VERSION ""

NS_ :

BS_:

BU_: ACM

VAL_TABLE_ Rolling_Counter_0x85 15 "Invalid";
VAL_TABLE_ ACM_Crash_Sts 3 "Invalid Value" 2 "Invalid Value" 1 "Crash_Detected" 0 "No_Event";
VAL_TABLE_ ACM_Airbag_Deployment_Status 3 "Invalid Value" 2 "Invalid Value" 1 "Airbag_Deployment" 0 "No_Airbag_Deployment";
VAL_TABLE_ ACM_Crash_Intensity 7 "Invalid_Value" 6 "Invalid_Value" 5 "Invalid_Value" 4 "Invalid_Value" 3 "Crash_Intensity_3" 2 "Crash_Intensity_2" 1 "Crash_Intensity_1" 0 "No_Crash";
VAL_TABLE_ ACM_Front_Crash 3 "Invalid Value" 2 "Invalid Value" 1 "Front_Crash_Detected" 0 "No_Event";
VAL_TABLE_ ACM_DriverSide_Crash 3 "Invalid Value" 2 "Invalid Value" 1 "Driverside_Crash_Detected" 0 "No_Event";
VAL_TABLE_ ACM_PassSide_Crash 3 "Invalid Value" 2 "Invalid Value" 1 "PassSide_Crash_Detected" 0 "No_Event";
VAL_TABLE_ ACM_Rear_Crash 3 "Invalid Value" 2 "Invalid Value" 1 "Rear_Crash_Detected" 0 "No_Event";
VAL_TABLE_ ACM_Rollover_Crash 3 "Invalid Value" 2 "Invalid Value" 1 "Rollover_Crash_Detected" 0 "No_Event";
VAL_TABLE_ Rolling_Counter_0x381 15 "Invalid";
VAL_TABLE_ ACM_Seat_Occupancy_Passenger 3 "Failure" 2 "Not_Available" 1 "Seat Occupied" 0 "Seat_Not_Occupied";
VAL_TABLE_ ACM_Seat_Occupancy_2nd_Row_Dri_reserved 3 "Failure" 2 "Not_Available" 1 "Seat Occupied" 0 "Seat_Not_Occupied";
VAL_TABLE_ ACM_Seat_Occupancy_2nd_Row_Pas_reserved 3 "Failure" 2 "Not_Available" 1 "Seat Occupied" 0 "Seat_Not_Occupied";
VAL_TABLE_ ACM_Seat_Occupancy_2nd_Row_Mid_reserved 3 "Failure" 2 "Not_Available" 1 "Seat Occupied" 0 "Seat_Not_Occupied";
VAL_TABLE_ ACM_Seat_Belt_Status_Passenger 3 "Failure" 2 "Not_Available" 1 "Buckled" 0 "Not_buckled";
VAL_TABLE_ ACM_Seat_Belt_Status_Driver 3 "Failure" 2 "Not_Available" 1 "Buckled" 0 "Not_buckled";
VAL_TABLE_ ACM_Seat_Belt_Status_2nd_Row_Dri_reserved 3 "Failure" 2 "Not_Available" 1 "Buckled" 0 "Not_buckled";
VAL_TABLE_ ACM_Seat_Belt_Status_2nd_Row_Mid_reserved 3 "Failure" 2 "Not_Available" 1 "Buckled" 0 "Not_buckled";
VAL_TABLE_ ACM_Seat_Belt_Status_2nd_Row_Pas_reserved 3 "Failure" 2 "Not_Available" 1 "Buckled" 0 "Not_buckled";
VAL_TABLE_ ACM_Seat_Belt_Status_3rd_Row_Dri_reserved 3 "Failure" 2 "Not_Available" 1 "Buckled" 0 "Not_buckled";
VAL_TABLE_ ACM_Seat_Belt_Status_3rd_Row_Pas_reserved 3 "Failure" 2 "Not_Available" 1 "Buckled" 0 "Not_buckled";
VAL_TABLE_ Rolling_Counter_0x488 15 "Invalid";
VAL_TABLE_ ACM_Malfunction 0 "ACM_Failure" 1 "ACM_Normal_Operation";
VAL_TABLE_ ACM_Pre_Drive_Check 0 "ACM_Pre_Drive_Check" 1 "ACM_Normal_Operation";
VAL_TABLE_ ACM_in_Plant_Mode 0 "ACM_in_Plant_Mode" 1 "ACM_in_Normal_Mode";
VAL_TABLE_ ACM_PAB_Suppression 0 "Not_Suppressed" 1 "Suppressed" 2 "Function Failure" 3 "Invalid_Value";
VAL_TABLE_ ACM_Airbag_Disabled 0 "ACM_AirBag_Disabled" 1 "ACM_Normal_Operation";
VAL_TABLE_ ACM_Development_Calibration 0 "ACM_Dev_Calibrated" 1 "ACM_Normal_Operation";
VAL_TABLE_ ACM_In_Disposal_Mode 0 "ACM_In_Disposal_Mode" 1 "ACM_Normal_Operation";
VAL_TABLE_ ACM_Seatbelt_Reminder_Request 0 "Seatbelt reminder NOT activated" 1 "Seatbelt reminder activated";
VAL_TABLE_ ACM_SBR_Chime_Req 0 "No Active Chime" 1 "Active Chime";
VAL_TABLE_ ACM_SBR_Blinking_Req 0 "No Blinking" 1 "Blinking 1Hz";
VAL_TABLE_ Rolling_Counter_0x106 15 "Invalid";
VAL_TABLE_ BCM_HighBeamSts 0 "OFF" 1 "ON" 2 "Fault (Reserved)" 3 "Signal Invalid";
VAL_TABLE_ BCM_LowBeamSts 0 "OFF" 1 "ON" 2 "Fault (Reserved)" 3 "Signal Invalid";
VAL_TABLE_ BCM_PosLmpSts 0 "OFF" 1 "ON" 2 "Fault (Reserved)" 3 "Signal Invalid";
VAL_TABLE_ BCM_TurnIndicatorSts 0 "OFF" 1 "Left On" 2 "Right On" 3 "Left and Right On";
VAL_TABLE_ BCM_DayRunningLampSts_reserved 0 "OFF" 1 "ON" 2 "Fault (Reserved)" 3 "Signal Invalid";
VAL_TABLE_ BCM_ReverseLightSts 0 "OFF" 1 "ON" 2 "Fault (Reserved)" 3 "Signal Invalid";
VAL_TABLE_ BCM_StopLightSts 0 "OFF" 1 "ON" 2 "Fault (Reserved)" 3 "Signal Invalid";
VAL_TABLE_ BCM_Fr_Dimming_dome_lampSts 0 "OFF" 1 "ON" 2 "Fault (Reserved)" 3 "Signal Invalid";
VAL_TABLE_ BCM_Heated_rearglass 0 "OFF" 1 "ON" 2 "Fault (Reserved)" 3 "Signal Invalid";
VAL_TABLE_ BCM_BsdLightSts 0 "OFF" 1 "Left On" 2 "Right On" 3 "Left and Right On";
VAL_TABLE_ BCM_STAT_LightActivation 7 "Signal invalid" 6 "Reserved" 5 "Reserved" 4 "Reserved" 3 "AutoLight" 2 "LowBeam" 1 "PositionLight" 0 "OFF";
VAL_TABLE_ BCM_STAT_InteriorLight 3 "Signal invalid" 2 "Reserved" 1 "ON" 0 "OFF";
VAL_TABLE_ Rolling_Counter_0x109 15 "Invalid";
VAL_TABLE_ BCM_STAT_HazardWarn 3 "Signal invalid" 2 "Reserved" 1 "Active" 0 "Not active";
VAL_TABLE_ BCM_STAT_Horn_Reserved 3 "Signal invalid" 2 "Reserved" 1 "ON" 0 "OFF";
VAL_TABLE_ BCM_STAT_WiperStalkSW 7 "Invalid" 6 "Reserved" 5 "Reserved" 4 "High" 3 "Low/Mist" 2 "Auto" 1 "OFF" 0 "Mist (reserved)";
VAL_TABLE_ BCM_STAT_WiperStalkSW2 7 "Invalid" 6 "Reserved" 5 "Reserved" 4 "wash(Front wash)" 3 "wiper&wash" 2 "wiper (rear wiper)" 1 "OFF(rear wiper)" 0 "wiper&wash(rear wiper and rear wash)";
VAL_TABLE_ BCM_LigntSensor 1 "invalid" 0 "valid";
VAL_TABLE_ BCM_STAT_lampStalkSW1 7 "Invalid" 6 "Reserved" 5 "Reserved" 4 "Reserved" 3 "OFF" 2 "positionlight" 1 "Lowbeam" 0 "Auto";
VAL_TABLE_ BCM_STAT_lampStalkSW2 3 "Invalid" 2 "neutral status" 1 "HighBeam" 0 "FlashHighBeam";
VAL_TABLE_ Rolling_Counter_0x10a 15 "Invalid";
VAL_TABLE_ BCM_LVTop_up 1 "start Top up" 0 "stop Top up";
VAL_TABLE_ Rolling_Counter_0x112 15 "Invalid";
VAL_TABLE_ STAT_Terminal 7 "Signal invalid" 6 "Reserved" 5 "Reserved" 4 "SW update OTA (Not used in VFe34)" 3 "Engine start (eMotor running)" 2 "ON (Driver Present)" 1 "ACC (Park)" 0 "OFF(Comfort Enable)";
VAL_TABLE_ STAT_CL30s_L_Reserved 3 "Signal invalid" 2 "Failure" 1 "ON" 0 "OFF";
VAL_TABLE_ RollingCounter_0x342 15 "Invalid";
VAL_TABLE_ ABS_LRWhlSpdRaw 32767 "Invalid";
VAL_TABLE_ ABS_LRWhlSpdRawValid 1 "Valid" 0 "Invalid";
VAL_TABLE_ ABS_RRWhlSpdRaw 32767 "Invalid";
VAL_TABLE_ ABS_RRWhlSpdRawValid 1 "Valid" 0 "Invalid";
VAL_TABLE_ ABS_VehSpd 32767 "Invalid";
VAL_TABLE_ ABS_VehSpdValid 1 "Valid" 0 "Invalid";
VAL_TABLE_ RollingCounter_0x142 15 "Invalid";
VAL_TABLE_ AbsDiagSessionLampReq_Reserved 1 "lamp on" 0 "lamp off";
VAL_TABLE_ ABS_AbsCtrlActv 1 "active" 0 "inactive";
VAL_TABLE_ ABS_EbdFlgFlt 1 "failure" 0 "no failure";
VAL_TABLE_ ABS_AbsFlgFlt 1 "failure" 0 "no failure";
VAL_TABLE_ ABS_ESS_Active 1 "active" 0 "inactive";
VAL_TABLE_ ABS_LowBrakeFluid 1 "failure" 0 "no failure";
VAL_TABLE_ RollingCounter_0x132 15 "Invalid";
VAL_TABLE_ ESC_HSA_Control_Status 1 "active" 0 "inactive";
VAL_TABLE_ ESC_HSA_Status_Fault 1 " HSA Defective" 0 "HSA Normale";
VAL_TABLE_ ESC_TcsDisableSts 3 "signal invalid" 2 "reservred" 1 "disabled" 0 "enabled";
VAL_TABLE_ ESC_TcsCtrlActv 1 "active" 0 "inactive";
VAL_TABLE_ ESC_TcsFlgFlt 1 "failure" 0 "no failure";
VAL_TABLE_ ESC_EscDisableSts 1 "disabled" 0 "enabled";
VAL_TABLE_ ESC_EscCtrlActv 1 "active" 0 "inactive";
VAL_TABLE_ ESC_EscFlgFlt 1 "failure" 0 "no failure";
VAL_TABLE_ ESC_HBAFlgFlt 1 "failure" 0 "no failure";
VAL_TABLE_ ESC_HbaCtrlActv 1 "active" 0 "inactive";
VAL_TABLE_ ESC_SlopeGradeAngle 255 "Invalid";
VAL_TABLE_ ESC_MasterCylinderPressure 4095 "Invalid";
VAL_TABLE_ RollingCounter_0x3E2 15 "Invalid";
VAL_TABLE_ ESC_LateralACC 255 "Invalid";
VAL_TABLE_ ESC_LateralACC_Valid 1 "Valid" 0 "Invalid";
VAL_TABLE_ ESC_LongitudeACC 1023 "Invalid";
VAL_TABLE_ ESC_LongitudeACC_Valid 1 "Valid" 0 "Invalid";
VAL_TABLE_ ESC_VehDynYawRate 16383 "Invalid";
VAL_TABLE_ ESC_VehDynYawRate_Valid 1 "Valid" 0 "Invalid";
VAL_TABLE_ Rolling_counter_0x17E 15 "Invalid";
VAL_TABLE_ SAS_SteerWheelAngle 65535 "Invalid";
VAL_TABLE_ SAS_SteeringAngleValid 1 "Valid" 0 "Invalid";
VAL_TABLE_ SAS_SASStsSnsr 1 "sensor value valid" 0 "sensor value Invalid";
VAL_TABLE_ SAS_SteerWhlRotSpd 16383 "Invalid";
VAL_TABLE_ SAS_SteerWhlRotSpdStatus 1 "Valid" 0 "Invalid";
VAL_TABLE_ SAS_Calibrated 1 "Calibrated" 0 "Not Calibrated";
VAL_TABLE_ SAS_SASFailure 1 "No Failure" 0 "Failure";
VAL_TABLE_ RollingCounter_0x269 15 "Invalid";
VAL_TABLE_ VCU_VehicleHVStatus 3 "Reserved" 2 "ReadyToDrive" 1 "HV On" 0 "Not ready";
VAL_TABLE_ VCU_ActualGear 7 "Fault" 6 "Reserved" 5 "Reserved" 4 "Reserved" 3 "D" 2 "N" 1 "R" 0 "P reserved";
VAL_TABLE_ VCU_ActualGearValid 1 "nvalid" 0 "Valid";
VAL_TABLE_ VCU_AccPedalPosition 255 "Invalid";
VAL_TABLE_ VCU_AccPedalPositionValid 1 "Invalid" 0 "Valid";
VAL_TABLE_ VCU_TqReductionRqstResponse_Reserved 1 "active" 0 "inactive";
VAL_TABLE_ VCU_BrakePedalSts 3 "Invalid" 2 "Reserved" 1 "pressed" 0 "Not pressed";
VAL_TABLE_ CCU_ExternalTemperature 255 "Invaild";
VAL_TABLE_ CCU_ExternalTemperatureFailSts 1 "invalid" 0 "valid";
VAL_TABLE_ IPC_Sec 63 "Invalid";
VAL_TABLE_ IPC_Min 63 "Invalid";
VAL_TABLE_ IPC_Hour 31 "Invalid";
VAL_TABLE_ IPC_Day 31 "Invalid";
VAL_TABLE_ IPC_Month 15 "Invalid";
VAL_TABLE_ IPC_Year 255 "Invalid";
VAL_TABLE_ IPC_SelfCheckStatus 1 "self-check finish" 0 "self-checking";
VAL_TABLE_ Rolling_Counter_0x20C 15 "Invalid";
VAL_TABLE_ IPC_ODO 1048575 "Invalid";
VAL_TABLE_ VCU_RegenLevel_Feed 3 "invalid" 2 "High" 1 "Low" 0 "none";
VAL_TABLE_ VCU_RBCSts 1 "active" 0 "incative";
VAL_TABLE_ VCU_RDCSts 1 "active" 0 "incative";
VAL_TABLE_ VCU_Veh_ERR 1 "Error" 0 "Normal";
VAL_TABLE_ VCU_DrvSys_ERR 1 "Error" 0 "Normal";
VAL_TABLE_ VCU_PackSys_ERR 1 "Error" 0 "Normal";
VAL_TABLE_ VCU_TBOX_Veh_STS_Reserved 3 "Other" 2 "Off" 1 "Start" 0 "Invalid";
VAL_TABLE_ VCU_VehChg_STS 3 "Charge fault" 2 "Charging complete" 1 "Charging in progress" 0 "Charging not in progress";
VAL_TABLE_ VCU_BatterVoltage_Reserved 255 "Invalid";
VAL_TABLE_ VCU_BatteryVoltErr_Reserved 1 "warning" 0 "no warning";
VAL_TABLE_ VCU_MotorCoolingCircuitErr_Reserved 1 "Error" 0 "Normal";
VAL_TABLE_ VCU_PackCoolingCircuitErr_Reserved 1 "Error" 0 "Normal";
VAL_TABLE_ VCU_VehicleHVStatus 3 "Reserved" 2 "ReadyToDrive" 1 "HV On" 0 "Not ready";
VAL_TABLE_ VCU_InstantPowerConsump 1023 "Invalid";
VAL_TABLE_ VCU_AveragePowerConsump 1023 "Invalid";
VAL_TABLE_ VCU_BrakePedalSts 3 "Invalid" 2 "Reserved" 1 "pressed" 0 "Not pressed";
VAL_TABLE_ Rolling_Counter_0x1F8 15 "Invalid";
VAL_TABLE_ EDS_output_trq_FR 65535 "Invalid";
VAL_TABLE_ EDS_output_trqValid_FR 1 "valid" 0 "invalid";
VAL_TABLE_ EDS_Spd_FR 65535 "Invalid";
VAL_TABLE_ EDS_SpdValid_FR 1 "valid" 0 "invalid";
VAL_TABLE_ EDS_MotorDriveSts_FR 3 "Invaild" 2 "regen control" 1 "Drive control" 0 "Zero control";
VAL_TABLE_ EDS_Work_STS_FR 15 "invaild" 14 "power off" 13 "Failure" 12 "after run" 11 "shut down" 5 "HVReady" 4 "normal" 3 "precharge" 2 "standby" 1 "init" 0 "default";
VAL_TABLE_ EDS_powoff_req_FR 1 "(Request high voltage power down)" 0 "(No request)";
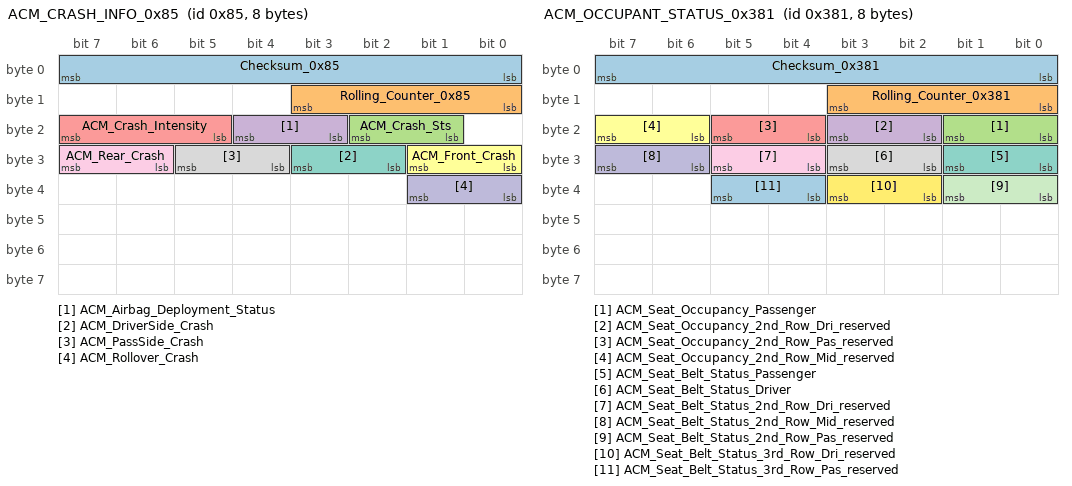
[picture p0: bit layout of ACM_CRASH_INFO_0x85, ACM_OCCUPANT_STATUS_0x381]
BO_ 133 ACM_CRASH_INFO_0x85: 8 ACM
 SG_ Checksum_0x85 : 7|8@0+ (1,0) [0|255] "" Vector__XXX
 SG_ Rolling_Counter_0x85 : 11|4@0+ (1,0) [0|15] "" Vector__XXX
 SG_ ACM_Crash_Sts : 18|2@0+ (1,0) [0|3] "" Vector__XXX
 SG_ ACM_Airbag_Deployment_Status : 20|2@0+ (1,0) [0|3] "" Vector__XXX
 SG_ ACM_Crash_Intensity : 23|3@0+ (1,0) [0|7] "" Vector__XXX
 SG_ ACM_Front_Crash : 25|2@0+ (1,0) [0|3] "" Vector__XXX
 SG_ ACM_DriverSide_Crash : 27|2@0+ (1,0) [0|3] "" Vector__XXX
 SG_ ACM_PassSide_Crash : 29|2@0+ (1,0) [0|3] "" Vector__XXX
 SG_ ACM_Rear_Crash : 31|2@0+ (1,0) [0|3] "" Vector__XXX
 SG_ ACM_Rollover_Crash : 33|2@0+ (1,0) [0|3] "" Vector__XXX
BO_ 897 ACM_OCCUPANT_STATUS_0x381: 8 ACM
 SG_ Checksum_0x381 : 7|8@0+ (1,0) [0|255] "" Vector__XXX
 SG_ Rolling_Counter_0x381 : 11|4@0+ (1,0) [0|15] "" Vector__XXX
 SG_ ACM_Seat_Occupancy_Passenger : 17|2@0+ (1,0) [0|3] "" Vector__XXX
 SG_ ACM_Seat_Occupancy_2nd_Row_Dri_reserved : 19|2@0+ (1,0) [0|3] "" Vector__XXX
 SG_ ACM_Seat_Occupancy_2nd_Row_Pas_reserved : 21|2@0+ (1,0) [0|3] "" Vector__XXX
 SG_ ACM_Seat_Occupancy_2nd_Row_Mid_reserved : 23|2@0+ (1,0) [0|3] "" Vector__XXX
 SG_ ACM_Seat_Belt_Status_Passenger : 25|2@0+ (1,0) [0|3] "" Vector__XXX
 SG_ ACM_Seat_Belt_Status_Driver : 27|2@0+ (1,0) [0|3] "" Vector__XXX
 SG_ ACM_Seat_Belt_Status_2nd_Row_Dri_reserved : 29|2@0+ (1,0) [0|3] "" Vector__XXX
 SG_ ACM_Seat_Belt_Status_2nd_Row_Mid_reserved : 31|2@0+ (1,0) [0|3] "" Vector__XXX
 SG_ ACM_Seat_Belt_Status_2nd_Row_Pas_reserved : 33|2@0+ (1,0) [0|3] "" Vector__XXX
 SG_ ACM_Seat_Belt_Status_3rd_Row_Dri_reserved : 35|2@0+ (1,0) [0|3] "" Vector__XXX
 SG_ ACM_Seat_Belt_Status_3rd_Row_Pas_reserved : 37|2@0+ (1,0) [0|3] "" Vector__XXX
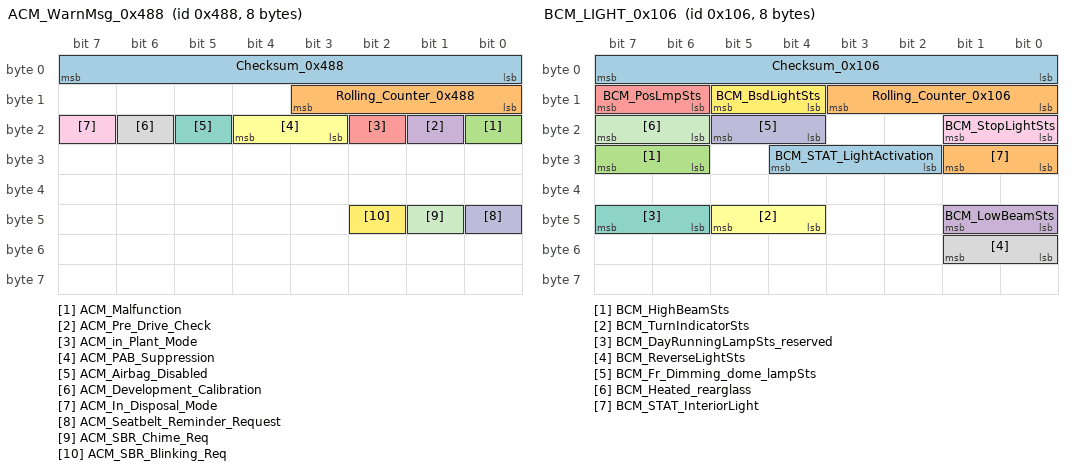
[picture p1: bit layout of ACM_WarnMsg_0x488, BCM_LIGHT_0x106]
BO_ 1160 ACM_WarnMsg_0x488: 8 ACM
 SG_ Checksum_0x488 : 7|8@0+ (1,0) [0|255] "" Vector__XXX
 SG_ Rolling_Counter_0x488 : 11|4@0+ (1,0) [0|15] "" Vector__XXX
 SG_ ACM_Malfunction : 16|1@0+ (1,0) [0|1] "" Vector__XXX
 SG_ ACM_Pre_Drive_Check : 17|1@0+ (1,0) [0|1] "Bit" Vector__XXX
 SG_ ACM_in_Plant_Mode : 18|1@0+ (1,0) [0|1] "Bit" Vector__XXX
 SG_ ACM_PAB_Suppression : 20|2@0+ (1,0) [0|3] "Bit" Vector__XXX
 SG_ ACM_Airbag_Disabled : 21|1@0+ (1,0) [0|1] "" Vector__XXX
 SG_ ACM_Development_Calibration : 22|1@0+ (1,0) [0|1] "" Vector__XXX
 SG_ ACM_In_Disposal_Mode : 23|1@0+ (1,0) [0|1] "" Vector__XXX
 SG_ ACM_Seatbelt_Reminder_Request : 40|1@0+ (1,0) [0|1] "" Vector__XXX
 SG_ ACM_SBR_Chime_Req : 41|1@0+ (1,0) [0|1] "" Vector__XXX
 SG_ ACM_SBR_Blinking_Req : 42|1@0+ (1,0) [0|1] "" Vector__XXX
BO_ 262 BCM_LIGHT_0x106: 8 Vector__XXX
 SG_ Checksum_0x106 : 7|8@0+ (1,0) [0|255] "" ACM
 SG_ Rolling_Counter_0x106 : 11|4@0+ (1,0) [0|15] "" ACM
 SG_ BCM_HighBeamSts : 31|2@0+ (1,0) [0|3] "" Vector__XXX
 SG_ BCM_LowBeamSts : 41|2@0+ (1,0) [0|3] "" Vector__XXX
 SG_ BCM_PosLmpSts : 15|2@0+ (1,0) [0|3] "" Vector__XXX
 SG_ BCM_TurnIndicatorSts : 45|2@0+ (1,0) [0|3] "" ACM
 SG_ BCM_DayRunningLampSts_reserved : 47|2@0+ (1,0) [0|3] "" Vector__XXX
 SG_ BCM_ReverseLightSts : 49|2@0+ (1,0) [0|3] "" Vector__XXX
 SG_ BCM_StopLightSts : 17|2@0+ (1,0) [0|3] "" Vector__XXX
 SG_ BCM_Fr_Dimming_dome_lampSts : 21|2@0+ (1,0) [0|3] "" Vector__XXX
 SG_ BCM_Heated_rearglass : 23|2@0+ (1,0) [0|3] "" Vector__XXX
 SG_ BCM_BsdLightSts : 13|2@0+ (1,0) [0|3] "" Vector__XXX
 SG_ BCM_STAT_LightActivation : 28|3@0+ (1,0) [0|7] "" Vector__XXX
 SG_ BCM_STAT_InteriorLight : 25|2@0+ (1,0) [0|3] "Bit" Vector__XXX
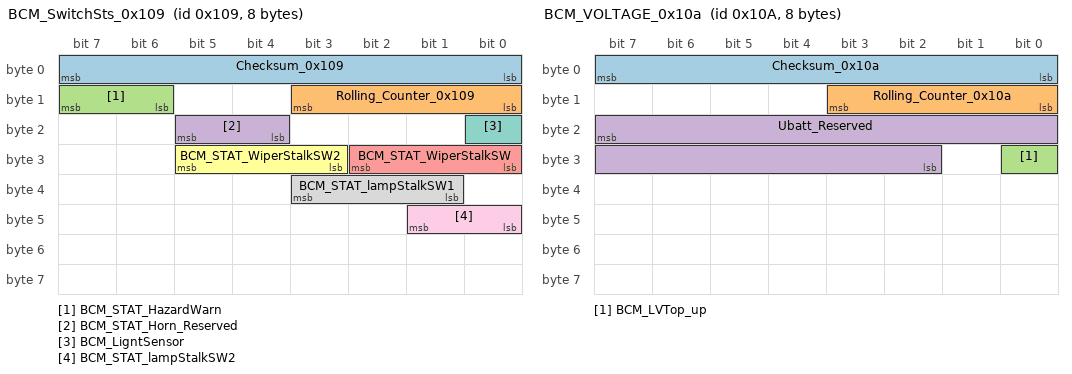
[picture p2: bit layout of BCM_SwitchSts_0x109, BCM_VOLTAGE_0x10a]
BO_ 265 BCM_SwitchSts_0x109: 8 Vector__XXX
 SG_ Checksum_0x109 : 7|8@0+ (1,0) [0|255] "" ACM
 SG_ Rolling_Counter_0x109 : 11|4@0+ (1,0) [0|15] "" ACM
 SG_ BCM_STAT_HazardWarn : 15|2@0+ (1,0) [0|3] "" ACM
 SG_ BCM_STAT_Horn_Reserved : 21|2@0+ (1,0) [0|3] "" Vector__XXX
 SG_ BCM_STAT_WiperStalkSW : 26|3@0+ (1,0) [0|7] "" Vector__XXX
 SG_ BCM_STAT_WiperStalkSW2 : 29|3@0+ (1,0) [0|7] "" Vector__XXX
 SG_ BCM_LigntSensor : 16|1@0+ (1,0) [0|1] "" Vector__XXX
 SG_ BCM_STAT_lampStalkSW1 : 35|3@0+ (1,0) [0|7] "" Vector__XXX
 SG_ BCM_STAT_lampStalkSW2 : 41|2@0+ (1,0) [0|3] "" Vector__XXX
BO_ 266 BCM_VOLTAGE_0x10a: 8 Vector__XXX
 SG_ Checksum_0x10a : 7|8@0+ (1,0) [0|255] "" ACM
 SG_ Rolling_Counter_0x10a : 11|4@0+ (1,0) [0|15] "" ACM
 SG_ BCM_LVTop_up : 24|1@0+ (1,0) [0|1] "" Vector__XXX
 SG_ Ubatt_Reserved : 23|14@0+ (0.001,3) [3|18] "V" ACM
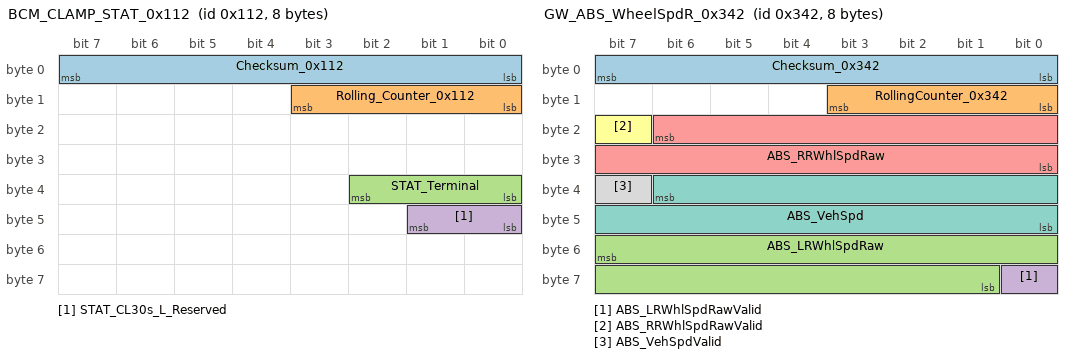
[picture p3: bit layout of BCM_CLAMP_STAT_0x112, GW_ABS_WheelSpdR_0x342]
BO_ 274 BCM_CLAMP_STAT_0x112: 8 Vector__XXX
 SG_ Checksum_0x112 : 7|8@0+ (1,0) [0|255] "" ACM
 SG_ Rolling_Counter_0x112 : 11|4@0+ (1,0) [0|15] "" ACM
 SG_ STAT_Terminal : 34|3@0+ (1,0) [0|7] "Bit" ACM
 SG_ STAT_CL30s_L_Reserved : 41|2@0+ (1,0) [0|3] "Bit" Vector__XXX
BO_ 834 GW_ABS_WheelSpdR_0x342: 8 Vector__XXX
 SG_ Checksum_0x342 : 7|8@0+ (1,0) [0|255] "" ACM
 SG_ RollingCounter_0x342 : 11|4@0+ (1,0) [0|15] "" ACM
 SG_ ABS_LRWhlSpdRaw : 55|15@0+ (0.01,0) [0|327.66] "kph" Vector__XXX
 SG_ ABS_LRWhlSpdRawValid : 56|1@0+ (1,0) [0|1] "" Vector__XXX
 SG_ ABS_RRWhlSpdRaw : 22|15@0+ (0.01,0) [0|327.66] "kph" Vector__XXX
 SG_ ABS_RRWhlSpdRawValid : 23|1@0+ (1,0) [0|1] "" Vector__XXX
 SG_ ABS_VehSpd : 38|15@0+ (0.01,0) [0|327.66] "kph" ACM
 SG_ ABS_VehSpdValid : 39|1@0+ (1,0) [0|1] "" ACM
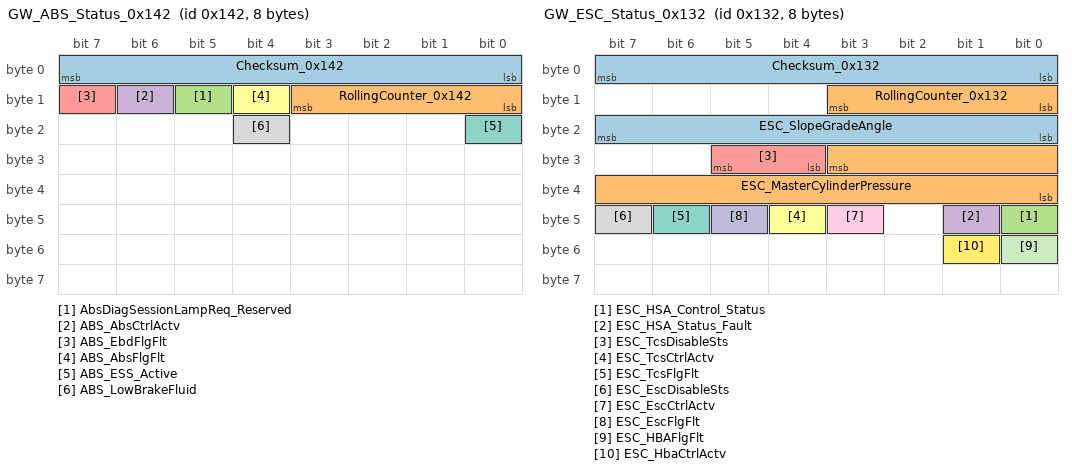
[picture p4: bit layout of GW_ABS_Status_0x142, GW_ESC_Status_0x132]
BO_ 322 GW_ABS_Status_0x142: 8 Vector__XXX
 SG_ Checksum_0x142 : 7|8@0+ (1,0) [0|255] "" ACM
 SG_ RollingCounter_0x142 : 11|4@0+ (1,0) [0|15] "" ACM
 SG_ AbsDiagSessionLampReq_Reserved : 13|1@0+ (1,0) [0|1] "" Vector__XXX
 SG_ ABS_AbsCtrlActv : 14|1@0+ (1,0) [0|1] "" ACM
 SG_ ABS_EbdFlgFlt : 15|1@0+ (1,0) [0|1] "" Vector__XXX
 SG_ ABS_AbsFlgFlt : 12|1@0+ (1,0) [0|1] "" ACM
 SG_ ABS_ESS_Active : 16|1@0+ (1,0) [0|1] "" Vector__XXX
 SG_ ABS_LowBrakeFluid : 20|1@0+ (1,0) [0|1] "" Vector__XXX
BO_ 306 GW_ESC_Status_0x132: 8 Vector__XXX
 SG_ Checksum_0x132 : 7|8@0+ (1,0) [0|255] "" ACM
 SG_ RollingCounter_0x132 : 11|4@0+ (1,0) [0|15] "" ACM
 SG_ ESC_HSA_Control_Status : 40|1@0+ (1,0) [0|1] "" Vector__XXX
 SG_ ESC_HSA_Status_Fault : 41|1@0+ (1,0) [0|1] "" Vector__XXX
 SG_ ESC_TcsDisableSts : 29|2@0+ (1,0) [0|3] "" Vector__XXX
 SG_ ESC_TcsCtrlActv : 44|1@0+ (1,0) [0|1] "" Vector__XXX
 SG_ ESC_TcsFlgFlt : 46|1@0+ (1,0) [0|1] "" Vector__XXX
 SG_ ESC_EscDisableSts : 47|1@0+ (1,0) [0|1] "" Vector__XXX
 SG_ ESC_EscCtrlActv : 43|1@0+ (1,0) [0|1] "" ACM
 SG_ ESC_EscFlgFlt : 45|1@0+ (1,0) [0|1] "" ACM
 SG_ ESC_HBAFlgFlt : 48|1@0+ (1,0) [0|1] "" Vector__XXX
 SG_ ESC_HbaCtrlActv : 49|1@0+ (1,0) [0|1] "" Vector__XXX
 SG_ ESC_SlopeGradeAngle : 23|8@0+ (0.35433,-45) [-45|45] "deg" Vector__XXX
 SG_ ESC_MasterCylinderPressure : 27|12@0+ (0.1,-100) [-100|309.4] "bar" Vector__XXX
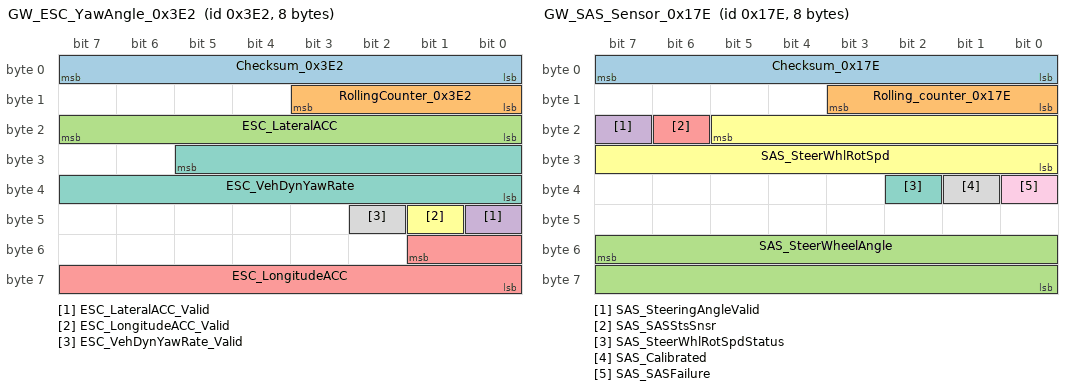
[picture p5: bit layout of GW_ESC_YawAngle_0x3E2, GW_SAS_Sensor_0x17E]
BO_ 994 GW_ESC_YawAngle_0x3E2: 8 Vector__XXX
 SG_ Checksum_0x3E2 : 7|8@0+ (1,0) [0|255] "" ACM
 SG_ RollingCounter_0x3E2 : 11|4@0+ (1,0) [0|15] "" ACM
 SG_ ESC_LateralACC : 23|8@0+ (0.01587,-2.0193) [-2.0193|2.0193] "g" Vector__XXX
 SG_ ESC_LateralACC_Valid : 40|1@0+ (1,0) [0|1] "" Vector__XXX
 SG_ ESC_LongitudeACC : 49|10@0+ (0.00392,-1.9929) [-1.9929|1.9929] "g" Vector__XXX
 SG_ ESC_LongitudeACC_Valid : 41|1@0+ (1,0) [0|1] "" Vector__XXX
 SG_ ESC_VehDynYawRate : 29|14@0+ (0.03125,-256) [-256|255.96875] "deg/s" ACM
 SG_ ESC_VehDynYawRate_Valid : 42|1@0+ (1,0) [0|1] "" ACM
BO_ 382 GW_SAS_Sensor_0x17E: 8 Vector__XXX
 SG_ Checksum_0x17E : 7|8@0+ (1,0) [0|255] "" ACM
 SG_ Rolling_counter_0x17E : 11|4@0+ (1,0) [0|15] "" ACM
 SG_ SAS_SteerWheelAngle : 55|16@0+ (0.0238,-780) [-780|779.7] "deg" ACM
 SG_ SAS_SteeringAngleValid : 23|1@0+ (1,0) [0|1] "" ACM
 SG_ SAS_SASStsSnsr : 22|1@0+ (1,0) [0|1] "" Vector__XXX
 SG_ SAS_SteerWhlRotSpd : 21|14@0+ (0.125,-1024) [-1024|1023.75] "degs" Vector__XXX
 SG_ SAS_SteerWhlRotSpdStatus : 34|1@0+ (1,0) [0|1] "" Vector__XXX
 SG_ SAS_Calibrated : 33|1@0+ (1,0) [0|1] "" Vector__XXX
 SG_ SAS_SASFailure : 32|1@0+ (1,0) [0|1] "" Vector__XXX
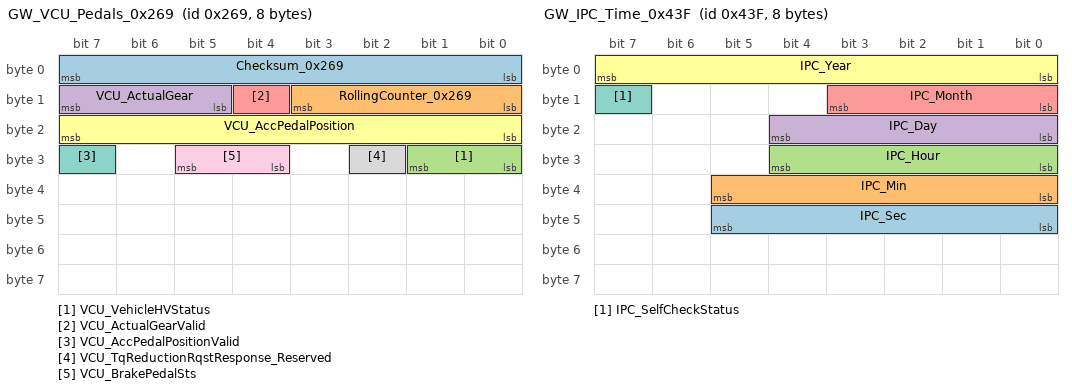
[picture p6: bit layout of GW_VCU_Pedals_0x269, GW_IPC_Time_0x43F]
BO_ 617 GW_VCU_Pedals_0x269: 8 Vector__XXX
 SG_ Checksum_0x269 : 7|8@0+ (1,0) [0|255] "" ACM
 SG_ RollingCounter_0x269 : 11|4@0+ (1,0) [0|15] "" ACM
 SG_ VCU_VehicleHVStatus : 25|2@0+ (1,0) [0|3] "" ACM
 SG_ VCU_ActualGear : 15|3@0+ (1,0) [0|7] "" Vector__XXX
 SG_ VCU_ActualGearValid : 12|1@0+ (1,0) [0|1] "" Vector__XXX
 SG_ VCU_AccPedalPosition : 23|8@0+ (0.4,0) [0|100] "%" ACM
 SG_ VCU_AccPedalPositionValid : 31|1@0+ (1,0) [0|1] "" ACM
 SG_ VCU_TqReductionRqstResponse_Reserved : 26|1@0+ (1,0) [0|1] "" Vector__XXX
 SG_ VCU_BrakePedalSts : 29|2@0+ (1,0) [0|3] "" ACM
BO_ 814 GW_CCU_Info_0x32E: 8 Vector__XXX
 SG_ CCU_ExternalTemperature : 7|8@0+ (0.5,-40) [-40|87] "°C" ACM
 SG_ CCU_ExternalTemperatureFailSts : 8|1@0+ (1,0) [0|1] "" ACM
BO_ 1087 GW_IPC_Time_0x43F: 8 Vector__XXX
 SG_ IPC_Sec : 45|6@0+ (1,0) [0|59] "second" ACM
 SG_ IPC_Min : 37|6@0+ (1,0) [0|59] "min" ACM
 SG_ IPC_Hour : 28|5@0+ (1,0) [0|23] "hour" ACM
 SG_ IPC_Day : 20|5@0+ (1,0) [1|31] "" ACM
 SG_ IPC_Month : 11|4@0+ (1,0) [1|12] "" ACM
 SG_ IPC_Year : 7|8@0+ (1,2000) [2000|2255] "" ACM
 SG_ IPC_SelfCheckStatus : 15|1@0+ (1,0) [0|1] "" ACM
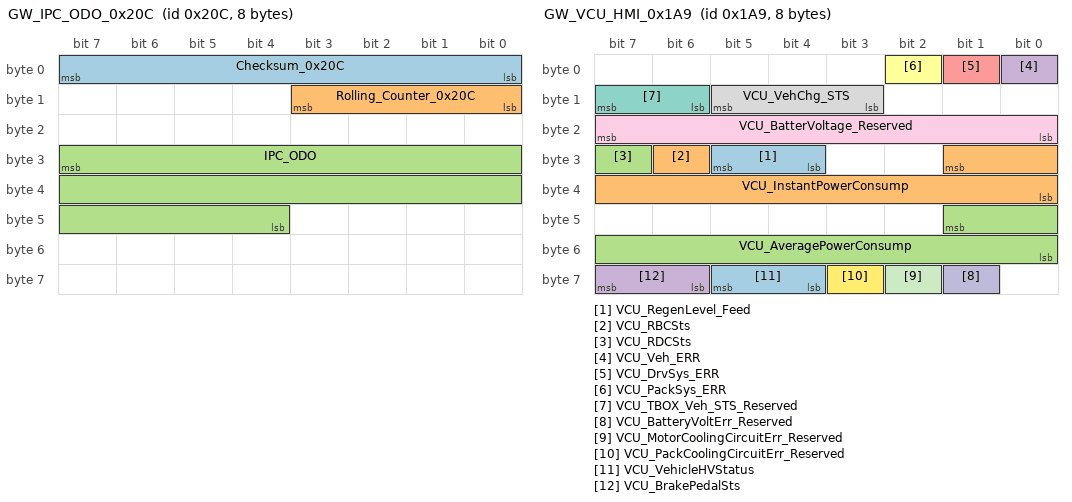
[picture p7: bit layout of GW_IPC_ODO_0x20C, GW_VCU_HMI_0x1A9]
BO_ 524 GW_IPC_ODO_0x20C: 8 Vector__XXX
 SG_ Checksum_0x20C : 7|8@0+ (1,0) [0|255] "" ACM
 SG_ Rolling_Counter_0x20C : 11|4@0+ (1,0) [0|15] "" ACM
 SG_ IPC_ODO : 31|20@0+ (1,0) [0|999999] "km" ACM
BO_ 425 GW_VCU_HMI_0x1A9: 8 Vector__XXX
 SG_ VCU_RegenLevel_Feed : 29|2@0+ (1,0) [0|3] "" Vector__XXX
 SG_ VCU_RBCSts : 30|1@0+ (1,0) [0|1] "" Vector__XXX
 SG_ VCU_RDCSts : 31|1@0+ (1,0) [0|1] "" Vector__XXX
 SG_ VCU_Veh_ERR : 0|1@0+ (1,0) [0|1] "" Vector__XXX
 SG_ VCU_DrvSys_ERR : 1|1@0+ (1,0) [0|1] "" Vector__XXX
 SG_ VCU_PackSys_ERR : 2|1@0+ (1,0) [0|1] "" Vector__XXX
 SG_ VCU_TBOX_Veh_STS_Reserved : 15|2@0+ (1,0) [0|3] "" Vector__XXX
 SG_ VCU_VehChg_STS : 13|3@0+ (1,0) [0|7] "" Vector__XXX
 SG_ VCU_BatterVoltage_Reserved : 23|8@0+ (0.07,0) [0|17.85] "V" ACM
 SG_ VCU_BatteryVoltErr_Reserved : 57|1@0+ (1,0) [0|1] "" Vector__XXX
 SG_ VCU_MotorCoolingCircuitErr_Reserved : 58|1@0+ (1,0) [0|1] "" Vector__XXX
 SG_ VCU_PackCoolingCircuitErr_Reserved : 59|1@0+ (1,0) [0|1] "" Vector__XXX
 SG_ VCU_VehicleHVStatus : 61|2@0+ (1,0) [0|3] "" Vector__XXX
 SG_ VCU_InstantPowerConsump : 25|10@0+ (0.1,0) [0|100] "kwh/100km" Vector__XXX
 SG_ VCU_AveragePowerConsump : 41|10@0+ (0.1,0) [0|100] "kwh/100km" Vector__XXX
 SG_ VCU_BrakePedalSts : 63|2@0+ (1,0) [0|3] "" Vector__XXX
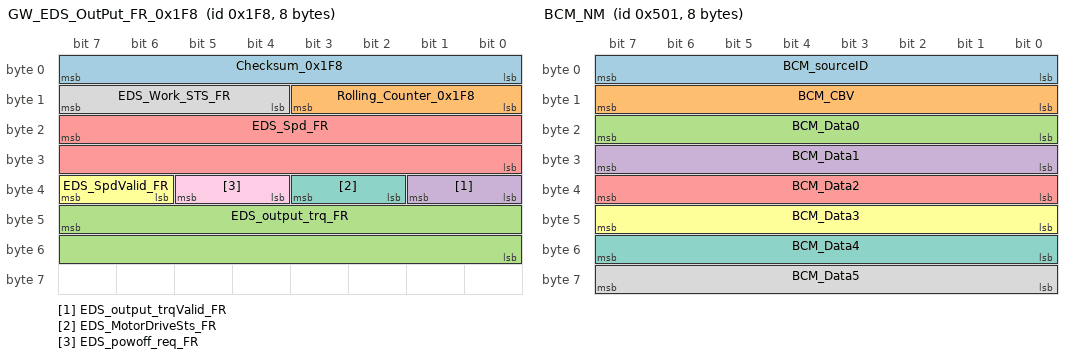
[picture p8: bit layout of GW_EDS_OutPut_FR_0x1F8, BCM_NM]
BO_ 504 GW_EDS_OutPut_FR_0x1F8: 8 Vector__XXX
 SG_ Checksum_0x1F8 : 7|8@0+ (1,0) [0|255] "" ACM
 SG_ Rolling_Counter_0x1F8 : 11|4@0+ (1,0) [0|15] "" ACM
 SG_ EDS_output_trq_FR : 47|16@0+ (1,-2000) [-2000|2000] "Nm" Vector__XXX
 SG_ EDS_output_trqValid_FR : 33|2@0+ (1,0) [0|1] "" Vector__XXX
 SG_ EDS_Spd_FR : 23|16@0+ (1,-20000) [-20000|20000] "rpm" ACM
 SG_ EDS_SpdValid_FR : 39|2@0+ (1,0) [0|1] "" ACM
 SG_ EDS_MotorDriveSts_FR : 35|2@0+ (1,0) [0|3] "" Vector__XXX
 SG_ EDS_Work_STS_FR : 15|4@0+ (1,0) [0|15] "" Vector__XXX
 SG_ EDS_powoff_req_FR : 37|2@0+ (1,0) [0|1] "" Vector__XXX
BO_ 1281 BCM_NM: 8 Vector__XXX
 SG_ BCM_sourceID : 7|8@0+ (1,0) [0|255] "" ACM
 SG_ BCM_CBV : 15|8@0+ (1,0) [0|255] "" ACM
 SG_ BCM_Data0 : 23|8@0+ (1,0) [0|255] "" ACM
 SG_ BCM_Data1 : 31|8@0+ (1,0) [0|255] "" ACM
 SG_ BCM_Data2 : 39|8@0+ (1,0) [0|255] "" ACM
 SG_ BCM_Data3 : 47|8@0+ (1,0) [0|255] "" ACM
 SG_ BCM_Data4 : 55|8@0+ (1,0) [0|255] "" ACM
 SG_ BCM_Data5 : 63|8@0+ (1,0) [0|255] "" ACM
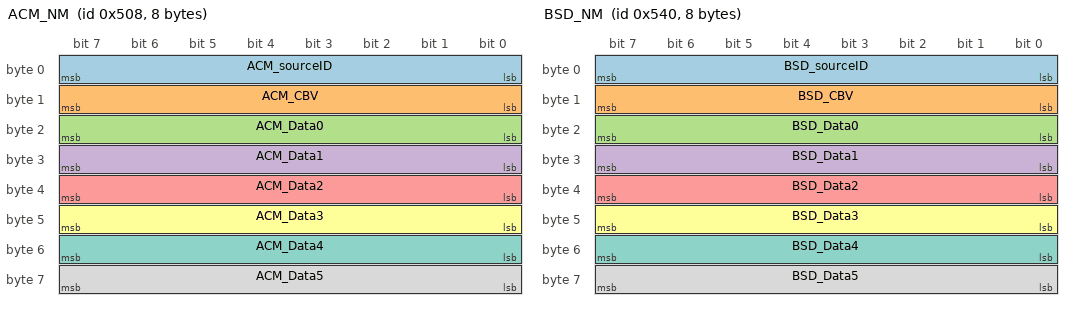
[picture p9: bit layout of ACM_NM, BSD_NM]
BO_ 1288 ACM_NM: 8 ACM
 SG_ ACM_sourceID : 7|8@0+ (1,0) [0|255] "" Vector__XXX
 SG_ ACM_CBV : 15|8@0+ (1,0) [0|255] "" Vector__XXX
 SG_ ACM_Data0 : 23|8@0+ (1,0) [0|255] "" Vector__XXX
 SG_ ACM_Data1 : 31|8@0+ (1,0) [0|255] "" Vector__XXX
 SG_ ACM_Data2 : 39|8@0+ (1,0) [0|255] "" Vector__XXX
 SG_ ACM_Data3 : 47|8@0+ (1,0) [0|255] "" Vector__XXX
 SG_ ACM_Data4 : 55|8@0+ (1,0) [0|255] "" Vector__XXX
 SG_ ACM_Data5 : 63|8@0+ (1,0) [0|255] "" Vector__XXX
BO_ 1344 BSD_NM: 8 Vector__XXX
 SG_ BSD_sourceID : 7|8@0+ (1,0) [0|255] "" ACM
 SG_ BSD_CBV : 15|8@0+ (1,0) [0|255] "" ACM
 SG_ BSD_Data0 : 23|8@0+ (1,0) [0|255] "" ACM
 SG_ BSD_Data1 : 31|8@0+ (1,0) [0|255] "" ACM
 SG_ BSD_Data2 : 39|8@0+ (1,0) [0|255] "" ACM
 SG_ BSD_Data3 : 47|8@0+ (1,0) [0|255] "" ACM
 SG_ BSD_Data4 : 55|8@0+ (1,0) [0|255] "" ACM
 SG_ BSD_Data5 : 63|8@0+ (1,0) [0|255] "" ACM
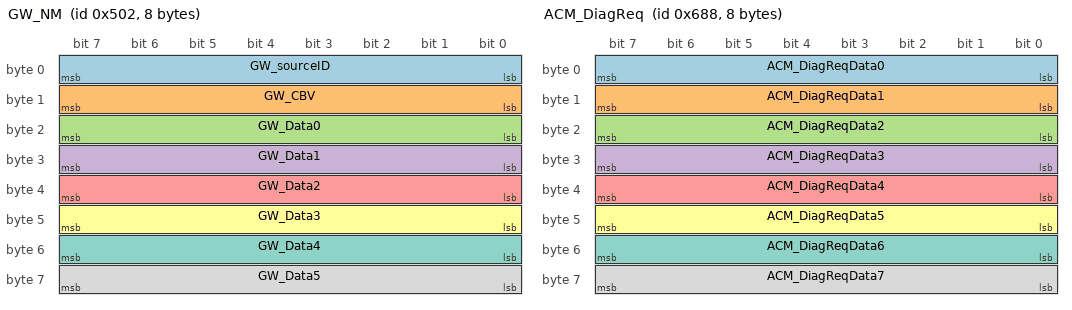
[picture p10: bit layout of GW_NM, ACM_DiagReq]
BO_ 1282 GW_NM: 8 Vector__XXX
 SG_ GW_sourceID : 7|8@0+ (1,0) [0|255] "" ACM
 SG_ GW_CBV : 15|8@0+ (1,0) [0|255] "" ACM
 SG_ GW_Data0 : 23|8@0+ (1,0) [0|255] "" ACM
 SG_ GW_Data1 : 31|8@0+ (1,0) [0|255] "" ACM
 SG_ GW_Data2 : 39|8@0+ (1,0) [0|255] "" ACM
 SG_ GW_Data3 : 47|8@0+ (1,0) [0|255] "" ACM
 SG_ GW_Data4 : 55|8@0+ (1,0) [0|255] "" ACM
 SG_ GW_Data5 : 63|8@0+ (1,0) [0|255] "" ACM
BO_ 1672 ACM_DiagReq: 8 Vector__XXX
 SG_ ACM_DiagReqData0 : 7|8@0+ (1,0) [0|255] "" ACM
 SG_ ACM_DiagReqData1 : 15|8@0+ (1,0) [0|255] "" ACM
 SG_ ACM_DiagReqData2 : 23|8@0+ (1,0) [0|255] "" ACM
 SG_ ACM_DiagReqData3 : 31|8@0+ (1,0) [0|255] "" ACM
 SG_ ACM_DiagReqData4 : 39|8@0+ (1,0) [0|255] "" ACM
 SG_ ACM_DiagReqData5 : 47|8@0+ (1,0) [0|255] "" ACM
 SG_ ACM_DiagReqData6 : 55|8@0+ (1,0) [0|255] "" ACM
 SG_ ACM_DiagReqData7 : 63|8@0+ (1,0) [0|255] "" ACM
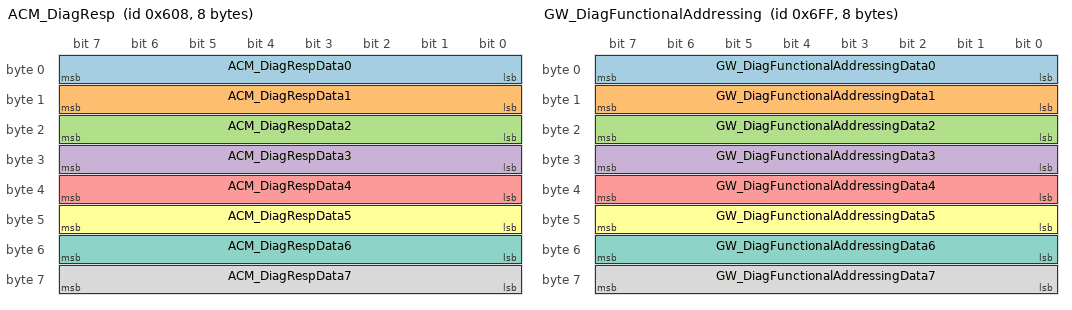
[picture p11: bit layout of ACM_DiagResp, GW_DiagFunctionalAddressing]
BO_ 1544 ACM_DiagResp: 8 ACM
 SG_ ACM_DiagRespData0 : 7|8@0+ (1,0) [0|255] "" Vector__XXX
 SG_ ACM_DiagRespData1 : 15|8@0+ (1,0) [0|255] "" Vector__XXX
 SG_ ACM_DiagRespData2 : 23|8@0+ (1,0) [0|255] "" Vector__XXX
 SG_ ACM_DiagRespData3 : 31|8@0+ (1,0) [0|255] "" Vector__XXX
 SG_ ACM_DiagRespData4 : 39|8@0+ (1,0) [0|255] "" Vector__XXX
 SG_ ACM_DiagRespData5 : 47|8@0+ (1,0) [0|255] "" Vector__XXX
 SG_ ACM_DiagRespData6 : 55|8@0+ (1,0) [0|255] "" Vector__XXX
 SG_ ACM_DiagRespData7 : 63|8@0+ (1,0) [0|255] "" Vector__XXX
BO_ 1791 GW_DiagFunctionalAddressing: 8 Vector__XXX
 SG_ GW_DiagFunctionalAddressingData0 : 7|8@0+ (1,0) [0|255] "" ACM
 SG_ GW_DiagFunctionalAddressingData1 : 15|8@0+ (1,0) [0|255] "" ACM
 SG_ GW_DiagFunctionalAddressingData2 : 23|8@0+ (1,0) [0|255] "" ACM
 SG_ GW_DiagFunctionalAddressingData3 : 31|8@0+ (1,0) [0|255] "" ACM
 SG_ GW_DiagFunctionalAddressingData4 : 39|8@0+ (1,0) [0|255] "" ACM
 SG_ GW_DiagFunctionalAddressingData5 : 47|8@0+ (1,0) [0|255] "" ACM
 SG_ GW_DiagFunctionalAddressingData6 : 55|8@0+ (1,0) [0|255] "" ACM
 SG_ GW_DiagFunctionalAddressingData7 : 63|8@0+ (1,0) [0|255] "" ACM
CM_ SG_ 133 Checksum_0x85 "Checksum";
CM_ SG_ 133 Rolling_Counter_0x85 "Rolling Counter";
CM_ SG_ 133 ACM_Crash_Sts "Crash status";
CM_ SG_ 133 ACM_Airbag_Deployment_Status "Signal to indicate if airbag/pretensioner/pyrofuse is deployed";
CM_ SG_ 133 ACM_Crash_Intensity "Indicate crash intensity level";
CM_ SG_ 133 ACM_Front_Crash "Output information for direction of crash";
CM_ SG_ 133 ACM_DriverSide_Crash "Output information for direction of crash";
CM_ SG_ 133 ACM_PassSide_Crash "Output information for direction of crash";
CM_ SG_ 133 ACM_Rear_Crash "Output information for direction of crash";
CM_ SG_ 133 ACM_Rollover_Crash "Output information for direction of crash";
CM_ SG_ 897 Checksum_0x381 "Checksum";
CM_ SG_ 897 Rolling_Counter_0x381 "Rolling Counter";
CM_ SG_ 897 ACM_Seat_Occupancy_Passenger "Signal to indicate status of occupancy";
CM_ SG_ 897 ACM_Seat_Occupancy_2nd_Row_Dri_reserved "Signal to indicate status of occupancy";
CM_ SG_ 897 ACM_Seat_Occupancy_2nd_Row_Pas_reserved "Signal to indicate status of occupancy";
CM_ SG_ 897 ACM_Seat_Occupancy_2nd_Row_Mid_reserved "Signal to indicate status of occupancy";
CM_ SG_ 897 ACM_Seat_Belt_Status_Passenger "Seatbelt status for seatbelt reminder function";
CM_ SG_ 897 ACM_Seat_Belt_Status_Driver "Seatbelt status for seatbelt reminder function";
CM_ SG_ 897 ACM_Seat_Belt_Status_2nd_Row_Dri_reserved "Seatbelt status for seatbelt reminder function";
CM_ SG_ 897 ACM_Seat_Belt_Status_2nd_Row_Mid_reserved "Seatbelt status for seatbelt reminder function";
CM_ SG_ 897 ACM_Seat_Belt_Status_2nd_Row_Pas_reserved "Seatbelt status for seatbelt reminder function";
CM_ SG_ 897 ACM_Seat_Belt_Status_3rd_Row_Dri_reserved "Seatbelt status for seatbelt reminder function";
CM_ SG_ 897 ACM_Seat_Belt_Status_3rd_Row_Pas_reserved "Seatbelt status for seatbelt reminder function";
CM_ SG_ 1160 Checksum_0x488 "Checksum";
CM_ SG_ 1160 Rolling_Counter_0x488 "Rolling Counter";
CM_ SG_ 1160 ACM_Malfunction "ACM Malfunction (trigger airbag warning lamp)";
CM_ SG_ 1160 ACM_Pre_Drive_Check "ACM status after pre-drive check (trigger airbag warning lamp if any failure)";
CM_ SG_ 1160 ACM_in_Plant_Mode "ACM plant mode status (trigger airbag warning lamp)";
CM_ SG_ 1160 ACM_PAB_Suppression "ACM suppress passenger airbag (front AB 1st stage, front AB 2nd stage, knee AB). This is used to trigger PAB indicator in MHU's display.";
CM_ SG_ 1160 ACM_Airbag_Disabled "ACM airbag disabled status due to Algo disabled or Firing disabled due to diagnostic or inert calibration file is flashed (trigger Airbag warning lamp when airbag is disabled)";
CM_ SG_ 1160 ACM_Development_Calibration "ACM calibration file status indicate whether ACM is flashed with calibration file for development purpose only (trigger Airbag warning lamp and chime when ACM is flashed with development calibration file)";
CM_ SG_ 1160 ACM_In_Disposal_Mode "ACM disposal mode status (trigger airbag warning lamp when ACM in disposal mode)";
CM_ SG_ 1160 ACM_Seatbelt_Reminder_Request "ACM request seatbelt reminder (1 signal for whole front and rear seats)";
CM_ SG_ 1160 ACM_SBR_Chime_Req "ACM request chime to MHU for seatbelt reminder front row";
CM_ SG_ 1160 ACM_SBR_Blinking_Req "ACM send blinking request to MHU (trigger blinking of seatbelt reminder lamp)";
CM_ SG_ 262 Checksum_0x106 "Checksum";
CM_ SG_ 262 Rolling_Counter_0x106 "Rolling_Counter";
CM_ SG_ 262 BCM_HighBeamSts "High beam output Status";
CM_ SG_ 262 BCM_LowBeamSts "Low beam output  Status";
CM_ SG_ 262 BCM_PosLmpSts "Position light output Status";
CM_ SG_ 262 BCM_TurnIndicatorSts "Turn light output  Status";
CM_ SG_ 262 BCM_DayRunningLampSts_reserved "DayRunning Lamp output Status";
CM_ SG_ 262 BCM_ReverseLightSts "Reverse light output Status";
CM_ SG_ 262 BCM_StopLightSts "Stop light output Status";
CM_ SG_ 262 BCM_Fr_Dimming_dome_lampSts "Dimming dome lamp Front Status";
CM_ SG_ 262 BCM_Heated_rearglass "Heate Rear Glass  Feedback";
CM_ SG_ 262 BCM_BsdLightSts "Indicates BSD status";
CM_ SG_ 262 BCM_STAT_LightActivation "Status of light";
CM_ SG_ 262 BCM_STAT_InteriorLight "status of backlight illumination";
CM_ SG_ 265 Checksum_0x109 "Checksum";
CM_ SG_ 265 Rolling_Counter_0x109 "Rolling_Counter";
CM_ SG_ 265 BCM_STAT_HazardWarn "Hazard Warning switch activation";
CM_ SG_ 265 BCM_STAT_Horn_Reserved "Status switch horn";
CM_ SG_ 265 BCM_STAT_WiperStalkSW "Status of Wiper stalk SW";
CM_ SG_ 265 BCM_STAT_WiperStalkSW2 "Status of Wiper stalk SW2(rear wiper and washer)";
CM_ SG_ 265 BCM_LigntSensor "BCM  LIGHT  SENSOR State";
CM_ SG_ 265 BCM_STAT_lampStalkSW1 "the position of stalk which control the Master light switch status";
CM_ SG_ 265 BCM_STAT_lampStalkSW2 "the position of stalk which control the low beam and high beam status";
CM_ SG_ 266 Checksum_0x10a "Checksum";
CM_ SG_ 266 Rolling_Counter_0x10a "Rolling_Counter";
CM_ SG_ 266 BCM_LVTop_up "LV  battery top up requice signal";
CM_ SG_ 266 Ubatt_Reserved "Battery Voltage(UBatt to be received by all modules,Required for DTC snapshots)";
CM_ SG_ 274 Checksum_0x112 "Checksum";
CM_ SG_ 274 Rolling_Counter_0x112 "Rolling_Counter";
CM_ SG_ 274 STAT_Terminal "Represent the status of physical terminal(STAT_Terminal to be received by all modules,Required for DTC snapshots and for FOTA)";
CM_ SG_ 274 STAT_CL30s_L_Reserved "Status Clamp 30s Logical ON/OFF";
CM_ SG_ 834 Checksum_0x342 "Check sum";
CM_ SG_ 834 RollingCounter_0x342 "Rolling Counter";
CM_ SG_ 834 ABS_LRWhlSpdRaw "Current Raw wheel speed information of rear left wheel.";
CM_ SG_ 834 ABS_LRWhlSpdRawValid "Current Raw wheel speed information valid flag of rear left wheel.";
CM_ SG_ 834 ABS_RRWhlSpdRaw "Current Raw wheel speed information of rear right wheel.";
CM_ SG_ 834 ABS_RRWhlSpdRawValid "Current Raw wheel speed information valid flag of rear right wheel";
CM_ SG_ 834 ABS_VehSpd "Current Longitudinal Vehicle Speed";
CM_ SG_ 834 ABS_VehSpdValid "Speed Valid Flag";
CM_ SG_ 322 Checksum_0x142 "check sum";
CM_ SG_ 322 RollingCounter_0x142 "Rolling counter";
CM_ SG_ 322 AbsDiagSessionLampReq_Reserved "ABS or ESC is currently in safety system diagnostic  session,(DVT mode) need cluster to turn on ESC/TCS, EBD, ABS fault lamp";
CM_ SG_ 322 ABS_AbsCtrlActv "ABS status(Indiacte ABS  function is active or not.When ABS intervention starts,it sets as 1)ABS";
CM_ SG_ 322 ABS_EbdFlgFlt "The EBD system fault, The EBD warning lamp should be open,The signal will be set as  whenEBD is disable due to faultEBD";
CM_ SG_ 322 ABS_AbsFlgFlt "The ABS system fault, The ABS warning lamp should be open,The signal will be set as whenABS is disable due to fault";
CM_ SG_ 322 ABS_ESS_Active "Emergency Stop Signaling Active,when emergency stop, this signal will set true";
CM_ SG_ 322 ABS_LowBrakeFluid "Detect the brake fluid level";
CM_ SG_ 306 Checksum_0x132 "check sum";
CM_ SG_ 306 RollingCounter_0x132 "Rolling counter";
CM_ SG_ 306 ESC_HSA_Control_Status "Indicate HSA function is active or not";
CM_ SG_ 306 ESC_HSA_Status_Fault "Detect the HAS Fault status";
CM_ SG_ 306 ESC_TcsDisableSts "Indicate the TCS function can use or not";
CM_ SG_ 306 ESC_TcsCtrlActv "Indicate TCS  function is active or not";
CM_ SG_ 306 ESC_TcsFlgFlt "Detect the TCS function fault status";
CM_ SG_ 306 ESC_EscDisableSts "Indicate the ESC function can use or not";
CM_ SG_ 306 ESC_EscCtrlActv "Indicate ESC  function is active or not";
CM_ SG_ 306 ESC_EscFlgFlt "Detect the ESC function fault status";
CM_ SG_ 306 ESC_HBAFlgFlt "Detect the HBA(Hydraulic Brake Assist) function status";
CM_ SG_ 306 ESC_HbaCtrlActv "Indicate HBA(Hydraulic Brake Assist)   function is active or not";
CM_ SG_ 306 ESC_SlopeGradeAngle "Vehicle slope,Uphill is negative (head is higher than tail), downhill is positive (tail is higher than head)";
CM_ SG_ 306 ESC_MasterCylinderPressure "Master cylinder pressure";
CM_ SG_ 994 Checksum_0x3E2 "check sum";
CM_ SG_ 994 RollingCounter_0x3E2 "Rolling counter";
CM_ SG_ 994 ESC_LateralACC "Indicate lateral acceleration";
CM_ SG_ 994 ESC_LateralACC_Valid "Valid flag of lateral acceleration";
CM_ SG_ 994 ESC_LongitudeACC "Indicate longitude acceleration";
CM_ SG_ 994 ESC_LongitudeACC_Valid "Valid flag of longitude acceleration";
CM_ SG_ 994 ESC_VehDynYawRate "Indicate the yaw rate";
CM_ SG_ 994 ESC_VehDynYawRate_Valid "Valid flag of yaw rate";
CM_ SG_ 382 Checksum_0x17E "Check sum";
CM_ SG_ 382 Rolling_counter_0x17E "Rolling Counter";
CM_ SG_ 382 SAS_SteerWheelAngle "The current angle of the steering wheel(Positive, to left; Negative, to right)";
CM_ SG_ 382 SAS_SteeringAngleValid "Effective signal for steering angle";
CM_ SG_ 382 SAS_SASStsSnsr "the flag of  SAS status Punch:Steering angle status";
CM_ SG_ 382 SAS_SteerWhlRotSpd "The current rotation speed of the steering wheel.";
CM_ SG_ 382 SAS_SteerWhlRotSpdStatus "The status of SteerWheel Rotation Speed valid";
CM_ SG_ 382 SAS_Calibrated "SAS calibration state of Steer Angle Sensor";
CM_ SG_ 382 SAS_SASFailure "Angle sensor disabled.";
CM_ SG_ 617 Checksum_0x269 "Check sum";
CM_ SG_ 617 RollingCounter_0x269 "Rolling counter";
CM_ SG_ 617 VCU_VehicleHVStatus "Vehicle High voltage Ready State(VCU_VehicleHVStatus to be received by all modules,Used as a flash programming pre-condition (replacement for engine running)";
CM_ SG_ 617 VCU_ActualGear "actual gear";
CM_ SG_ 617 VCU_ActualGearValid "Indicate the current gear position";
CM_ SG_ 617 VCU_AccPedalPosition "Indicate the acceleraton pedal position";
CM_ SG_ 617 VCU_AccPedalPositionValid "Indicate the acceleration pedal position valid flag";
CM_ SG_ 617 VCU_TqReductionRqstResponse_Reserved "Indicate the response for the RBS/TCS request torqueRBS/TCS";
CM_ SG_ 617 VCU_BrakePedalSts "Brake Pedal Sts";
CM_ SG_ 814 CCU_ExternalTemperature "External Temperature";
CM_ SG_ 814 CCU_ExternalTemperatureFailSts "External Temperature Fail Sts";
CM_ SG_ 1087 IPC_Sec "Represents the current second.60 - 63 = Invalid";
CM_ SG_ 1087 IPC_Min "Represents the current minute. 60 - 63 = Invalid";
CM_ SG_ 1087 IPC_Hour "Represents the current hour, 24 - 30 = not used";
CM_ SG_ 1087 IPC_Day "Represents the current dayInvalid value = 0";
CM_ SG_ 1087 IPC_Month "Represents the current month.0, 13 to 15 = Invalid";
CM_ SG_ 1087 IPC_Year "Represents the current year.";
CM_ SG_ 1087 IPC_SelfCheckStatus "Power on self check status";
CM_ SG_ 524 Checksum_0x20C "Checksum";
CM_ SG_ 524 Rolling_Counter_0x20C "Rolling_Counter";
CM_ SG_ 524 IPC_ODO "odograph";
CM_ SG_ 425 VCU_RegenLevel_Feed "VCU current Feedback Set power regenerative level";
CM_ SG_ 425 VCU_RBCSts "Regenerative Braking";
CM_ SG_ 425 VCU_RDCSts "Regenerative coasted";
CM_ SG_ 425 VCU_Veh_ERR "Vehicle System Error";
CM_ SG_ 425 VCU_DrvSys_ERR "DriveSystemError";
CM_ SG_ 425 VCU_PackSys_ERR "StoredEnergySystemError";
CM_ SG_ 425 VCU_TBOX_Veh_STS_Reserved "Vehicle Status";
CM_ SG_ 425 VCU_VehChg_STS "Vehicle Charge Status";
CM_ SG_ 425 VCU_BatterVoltage_Reserved "BetteryVoltage";
CM_ SG_ 425 VCU_BatteryVoltErr_Reserved "Indicate the generator is warning when Mechanical flag or Electrical flag is active (Reserved)（）";
CM_ SG_ 425 VCU_MotorCoolingCircuitErr_Reserved "Motor cooling loop failure state (Reserved)";
CM_ SG_ 425 VCU_PackCoolingCircuitErr_Reserved "Battery pack cooling loop failure state (Reserved)";
CM_ SG_ 425 VCU_VehicleHVStatus "Vehicle High voltage Ready State(VCU_VehicleHVStatus to be received by all modules,Used as a flash programming pre-condition (replacement for engine running)";
CM_ SG_ 425 VCU_InstantPowerConsump "Instant power consumption";
CM_ SG_ 425 VCU_AveragePowerConsump "Average power comsumption";
CM_ SG_ 425 VCU_BrakePedalSts "Brake Pedal Sts";
CM_ SG_ 504 Checksum_0x1F8 "Check sum";
CM_ SG_ 504 Rolling_Counter_0x1F8 "Rolling counter";
CM_ SG_ 504 EDS_output_trq_FR "Actual output torque of current EDS";
CM_ SG_ 504 EDS_output_trqValid_FR "Indicate the valid flag of current motor torque";
CM_ SG_ 504 EDS_Spd_FR "current motor speed";
CM_ SG_ 504 EDS_SpdValid_FR "Indicate the valid flag of current motor speed";
CM_ SG_ 504 EDS_MotorDriveSts_FR "The drive state of EDS";
CM_ SG_ 504 EDS_Work_STS_FR "EDS Work status";
CM_ SG_ 504 EDS_powoff_req_FR "If there is a serious failure in the running process of EDS, the high voltage of VCU will be requested";
CM_ SG_ 1281 BCM_sourceID "source ID";
CM_ SG_ 1281 BCM_CBV "CBV";
CM_ SG_ 1281 BCM_Data0 "Data0";
CM_ SG_ 1281 BCM_Data1 "Data1";
CM_ SG_ 1281 BCM_Data2 "Data2";
CM_ SG_ 1281 BCM_Data3 "Data3";
CM_ SG_ 1281 BCM_Data4 "Data4";
CM_ SG_ 1281 BCM_Data5 "Data5";
CM_ SG_ 1288 ACM_sourceID "source ID";
CM_ SG_ 1288 ACM_CBV "CBV";
CM_ SG_ 1288 ACM_Data0 "Data0";
CM_ SG_ 1288 ACM_Data1 "Data1";
CM_ SG_ 1288 ACM_Data2 "Data2";
CM_ SG_ 1288 ACM_Data3 "Data3";
CM_ SG_ 1288 ACM_Data4 "Data4";
CM_ SG_ 1288 ACM_Data5 "Data5";
CM_ SG_ 1344 BSD_sourceID "source ID";
CM_ SG_ 1344 BSD_CBV "CBV";
CM_ SG_ 1344 BSD_Data0 "Data0";
CM_ SG_ 1344 BSD_Data1 "Data1";
CM_ SG_ 1344 BSD_Data2 "Data2";
CM_ SG_ 1344 BSD_Data3 "Data3";
CM_ SG_ 1344 BSD_Data4 "Data4";
CM_ SG_ 1344 BSD_Data5 "Data5";
CM_ SG_ 1282 GW_sourceID "source ID";
CM_ SG_ 1282 GW_CBV "CBV";
CM_ SG_ 1282 GW_Data0 "Data0";
CM_ SG_ 1282 GW_Data1 "Data1";
CM_ SG_ 1282 GW_Data2 "Data2";
CM_ SG_ 1282 GW_Data3 "Data3";
CM_ SG_ 1282 GW_Data4 "Data4";
CM_ SG_ 1282 GW_Data5 "Data5";
CM_ SG_ 1672 ACM_DiagReqData0 "Data0";
CM_ SG_ 1672 ACM_DiagReqData1 "Data1";
CM_ SG_ 1672 ACM_DiagReqData2 "Data2";
CM_ SG_ 1672 ACM_DiagReqData3 "Data3";
CM_ SG_ 1672 ACM_DiagReqData4 "Data4";
CM_ SG_ 1672 ACM_DiagReqData5 "Data5";
CM_ SG_ 1672 ACM_DiagReqData6 "Data6";
CM_ SG_ 1672 ACM_DiagReqData7 "Data7";
CM_ SG_ 1544 ACM_DiagRespData0 "Data0";
CM_ SG_ 1544 ACM_DiagRespData1 "Data1";
CM_ SG_ 1544 ACM_DiagRespData2 "Data2";
CM_ SG_ 1544 ACM_DiagRespData3 "Data3";
CM_ SG_ 1544 ACM_DiagRespData4 "Data4";
CM_ SG_ 1544 ACM_DiagRespData5 "Data5";
CM_ SG_ 1544 ACM_DiagRespData6 "Data6";
CM_ SG_ 1544 ACM_DiagRespData7 "Data7";
CM_ SG_ 1791 GW_DiagFunctionalAddressingData0 "Data0";
CM_ SG_ 1791 GW_DiagFunctionalAddressingData1 "Data1";
CM_ SG_ 1791 GW_DiagFunctionalAddressingData2 "Data2";
CM_ SG_ 1791 GW_DiagFunctionalAddressingData3 "Data3";
CM_ SG_ 1791 GW_DiagFunctionalAddressingData4 "Data4";
CM_ SG_ 1791 GW_DiagFunctionalAddressingData5 "Data5";
CM_ SG_ 1791 GW_DiagFunctionalAddressingData6 "Data6";
CM_ SG_ 1791 GW_DiagFunctionalAddressingData7 "Data7";
BA_DEF_ BO_ "DiagRequest" ENUM "No","Yes";
BA_DEF_ BO_ "DiagResponse" ENUM "No","Yes";
BA_DEF_ BO_ "DiagState" ENUM "No","Yes";
BA_DEF_ BO_ "GenMsgCycleTime" INT 0 65535;
BA_DEF_ BO_ "GenMsgCycleTimeFast" INT 0 65535;
BA_DEF_ BO_ "GenMsgDelayTime" INT 0 65535;
BA_DEF_ BO_ "GenMsgILSupport" ENUM "No","Yes";
BA_DEF_ BO_ "GenMsgNrOfRepetition" INT 0 65535;
BA_DEF_ BO_ "GenMsgSendType" ENUM  "Cycle","Event","IfActive","CE","CA";
BA_DEF_ BO_ "NmAsrMessage" ENUM "No","Yes";
BA_DEF_ BO_ "NmMessage" ENUM "No","Yes";
BA_DEF_ SG_ "GenSigSendType" ENUM  "Cycle","OnWrite","OnWriteWithRepetition","OnChange","OnChangeWithRepetition","IfActive","IfActiveWithRepetition";
BA_DEF_ SG_ "GenSigStartValue" INT 0 2147483647;
BA_DEF_ SG_ "GenSigInvalidValue" INT 0 2147483647;
BA_DEF_ SG_ "GenSigInactiveValue" INT 0 2147483647;
BA_DEF_ BU_ "ILUsed" ENUM  "No","Yes";
BA_DEF_ BU_ "NmAsrCanMsgReducedTime" INT 320 640;
BA_DEF_ BU_ "NmAsrNode" ENUM  "No","Yes";
BA_DEF_  "Baudrate" INT 0 1000000;
BA_DEF_  "BusType" STRING;
BA_DEF_  "Manufacturer" STRING;
BA_DEF_  "NmAsrBaseAddress" HEX 0 2047;
BA_DEF_  "NmAsrCanMsgCycleTime" INT 0 65535;
BA_DEF_  "NmAsrMessageCount" INT 1 256;
BA_DEF_  "NmAsrRepeatMessageTime" INT 0 65535;
BA_DEF_  "NmAsrTimeoutTime" INT 0 65535;
BA_DEF_  "NmAsrWaitBusSleepTime" INT 0 65535;
BA_DEF_  "NmType" STRING;
BA_DEF_DEF_ "Baudrate" 500000;
BA_DEF_DEF_ "BusType" "CAN";
BA_DEF_DEF_ "DiagRequest" "No";
BA_DEF_DEF_ "DiagResponse" "No";
BA_DEF_DEF_ "DiagState" "No";
BA_DEF_DEF_ "GenMsgCycleTime" 0;
BA_DEF_DEF_ "GenMsgCycleTimeFast" 0;
BA_DEF_DEF_ "GenMsgDelayTime" 0;
BA_DEF_DEF_ "GenMsgILSupport" "Yes";
BA_DEF_DEF_ "GenMsgNrOfRepetition" 0;
BA_DEF_DEF_ "GenMsgSendType" "NoMsgSendType";
BA_DEF_DEF_ "GenSigSendType" "NoSigSendType";
BA_DEF_DEF_ "GenSigStartValue" 0;
BA_DEF_DEF_  "GenSigInvalidValue" 0;
BA_DEF_DEF_ "GenSigInactiveValue" 0;
BA_DEF_DEF_ "ILUsed" "Yes";
BA_DEF_DEF_ "Manufacturer" "Launch";
BA_DEF_DEF_ "NmAsrBaseAddress" 1280;
BA_DEF_DEF_ "NmAsrCanMsgCycleTime" 640;
BA_DEF_DEF_ "NmAsrCanMsgReducedTime" 320;
BA_DEF_DEF_ "NmAsrMessage" "No";
BA_DEF_DEF_ "NmAsrMessageCount" 128;
BA_DEF_DEF_ "NmAsrNode" "No";
BA_DEF_DEF_ "NmAsrRepeatMessageTime" 3200;
BA_DEF_DEF_ "NmAsrTimeoutTime" 2000;
BA_DEF_DEF_ "NmAsrWaitBusSleepTime" 1500;
BA_DEF_DEF_ "NmMessage" "No";
BA_DEF_DEF_ "NmType" "NmAsr";

BA_ "NmAsrNode" BU_ ACM 1;
BA_ "GenMsgSendType" BO_ 133 0;
BA_ "GenMsgCycleTime" BO_ 133 20;
BA_ "GenMsgSendType" BO_ 897 0;
BA_ "GenMsgCycleTime" BO_ 897 200;
BA_ "GenMsgSendType" BO_ 1160 0;
BA_ "GenMsgCycleTime" BO_ 1160 1000;
BA_ "GenMsgSendType" BO_ 262 0;
BA_ "GenMsgCycleTime" BO_ 262 20;
BA_ "GenMsgSendType" BO_ 265 0;
BA_ "GenMsgCycleTime" BO_ 265 30;
BA_ "GenMsgSendType" BO_ 266 0;
BA_ "GenMsgCycleTime" BO_ 266 100;
BA_ "GenMsgSendType" BO_ 274 0;
BA_ "GenMsgCycleTime" BO_ 274 100;
BA_ "GenMsgSendType" BO_ 834 0;
BA_ "GenMsgCycleTime" BO_ 834 10;
BA_ "GenMsgSendType" BO_ 322 0;
BA_ "GenMsgCycleTime" BO_ 322 20;
BA_ "GenMsgSendType" BO_ 306 0;
BA_ "GenMsgCycleTime" BO_ 306 20;
BA_ "GenMsgSendType" BO_ 994 0;
BA_ "GenMsgCycleTime" BO_ 994 20;
BA_ "GenMsgSendType" BO_ 382 0;
BA_ "GenMsgCycleTime" BO_ 382 10;
BA_ "GenMsgSendType" BO_ 617 0;
BA_ "GenMsgCycleTime" BO_ 617 20;
BA_ "GenMsgSendType" BO_ 814 0;
BA_ "GenMsgCycleTime" BO_ 814 50;
BA_ "GenMsgSendType" BO_ 1087 0;
BA_ "GenMsgCycleTime" BO_ 1087 1000;
BA_ "GenMsgSendType" BO_ 524 0;
BA_ "GenMsgCycleTime" BO_ 524 100;
BA_ "GenMsgSendType" BO_ 425 0;
BA_ "GenMsgCycleTime" BO_ 425 20;
BA_ "GenMsgSendType" BO_ 504 0;
BA_ "GenMsgCycleTime" BO_ 504 10;
BA_ "GenMsgSendType" BO_ 1281 2;
BA_ "GenMsgCycleTime" BO_ 1281 640;
BA_ "NmAsrMessage" BO_ 1281 1;
BA_ "NmMessage" BO_ 1281 1;
BA_ "GenMsgSendType" BO_ 1288 2;
BA_ "GenMsgCycleTime" BO_ 1288 640;
BA_ "NmAsrMessage" BO_ 1288 1;
BA_ "NmMessage" BO_ 1288 1;
BA_ "GenMsgSendType" BO_ 1344 2;
BA_ "GenMsgCycleTime" BO_ 1344 640;
BA_ "NmAsrMessage" BO_ 1344 1;
BA_ "NmMessage" BO_ 1344 1;
BA_ "GenMsgSendType" BO_ 1282 2;
BA_ "GenMsgCycleTime" BO_ 1282 640;
BA_ "NmAsrMessage" BO_ 1282 1;
BA_ "NmMessage" BO_ 1282 1;
BA_ "GenMsgSendType" BO_ 1672 1;
BA_ "DiagRequest" BO_ 1672 1;
BA_ "GenMsgSendType" BO_ 1544 1;
BA_ "DiagResponse" BO_ 1544 1;
BA_ "GenMsgSendType" BO_ 1791 1;
BA_ "DiagState" BO_ 1791 1;
BA_ "GenSigSendType" SG_ 133 Checksum_0x85 0;
BA_ "GenSigSendType" SG_ 133 Rolling_Counter_0x85 0;
BA_ "GenSigInvalidValue" SG_ 133 Rolling_Counter_0x85 15;
BA_ "GenSigSendType" SG_ 133 ACM_Crash_Sts 0;
BA_ "GenSigInvalidValue" SG_ 133 ACM_Crash_Sts 3;
BA_ "GenSigSendType" SG_ 133 ACM_Airbag_Deployment_Status 0;
BA_ "GenSigInvalidValue" SG_ 133 ACM_Airbag_Deployment_Status 3;
BA_ "GenSigSendType" SG_ 133 ACM_Crash_Intensity 0;
BA_ "GenSigInvalidValue" SG_ 133 ACM_Crash_Intensity 7;
BA_ "GenSigSendType" SG_ 133 ACM_Front_Crash 0;
BA_ "GenSigInvalidValue" SG_ 133 ACM_Front_Crash 3;
BA_ "GenSigSendType" SG_ 133 ACM_DriverSide_Crash 0;
BA_ "GenSigInvalidValue" SG_ 133 ACM_DriverSide_Crash 3;
BA_ "GenSigSendType" SG_ 133 ACM_PassSide_Crash 0;
BA_ "GenSigInvalidValue" SG_ 133 ACM_PassSide_Crash 3;
BA_ "GenSigSendType" SG_ 133 ACM_Rear_Crash 0;
BA_ "GenSigInvalidValue" SG_ 133 ACM_Rear_Crash 3;
BA_ "GenSigSendType" SG_ 133 ACM_Rollover_Crash 0;
BA_ "GenSigInvalidValue" SG_ 133 ACM_Rollover_Crash 3;
BA_ "GenSigSendType" SG_ 897 Checksum_0x381 0;
BA_ "GenSigSendType" SG_ 897 Rolling_Counter_0x381 0;
BA_ "GenSigInvalidValue" SG_ 897 Rolling_Counter_0x381 15;
BA_ "GenSigSendType" SG_ 897 ACM_Seat_Occupancy_Passenger 0;
BA_ "GenSigStartValue" SG_ 897 ACM_Seat_Occupancy_Passenger 2;
BA_ "GenSigSendType" SG_ 897 ACM_Seat_Occupancy_2nd_Row_Dri_reserved 0;
BA_ "GenSigStartValue" SG_ 897 ACM_Seat_Occupancy_2nd_Row_Dri_reserved 2;
BA_ "GenSigSendType" SG_ 897 ACM_Seat_Occupancy_2nd_Row_Pas_reserved 0;
BA_ "GenSigStartValue" SG_ 897 ACM_Seat_Occupancy_2nd_Row_Pas_reserved 2;
BA_ "GenSigSendType" SG_ 897 ACM_Seat_Occupancy_2nd_Row_Mid_reserved 0;
BA_ "GenSigStartValue" SG_ 897 ACM_Seat_Occupancy_2nd_Row_Mid_reserved 2;
BA_ "GenSigSendType" SG_ 897 ACM_Seat_Belt_Status_Passenger 0;
BA_ "GenSigSendType" SG_ 897 ACM_Seat_Belt_Status_Driver 0;
BA_ "GenSigSendType" SG_ 897 ACM_Seat_Belt_Status_2nd_Row_Dri_reserved 0;
BA_ "GenSigSendType" SG_ 897 ACM_Seat_Belt_Status_2nd_Row_Mid_reserved 0;
BA_ "GenSigSendType" SG_ 897 ACM_Seat_Belt_Status_2nd_Row_Pas_reserved 0;
BA_ "GenSigSendType" SG_ 897 ACM_Seat_Belt_Status_3rd_Row_Dri_reserved 0;
BA_ "GenSigStartValue" SG_ 897 ACM_Seat_Belt_Status_3rd_Row_Dri_reserved 2;
BA_ "GenSigSendType" SG_ 897 ACM_Seat_Belt_Status_3rd_Row_Pas_reserved 0;
BA_ "GenSigStartValue" SG_ 897 ACM_Seat_Belt_Status_3rd_Row_Pas_reserved 2;
BA_ "GenSigSendType" SG_ 1160 Checksum_0x488 0;
BA_ "GenSigSendType" SG_ 1160 Rolling_Counter_0x488 0;
BA_ "GenSigInvalidValue" SG_ 1160 Rolling_Counter_0x488 15;
BA_ "GenSigSendType" SG_ 1160 ACM_Malfunction 0;
BA_ "GenSigStartValue" SG_ 1160 ACM_Malfunction 1;
BA_ "GenSigSendType" SG_ 1160 ACM_Pre_Drive_Check 0;
BA_ "GenSigSendType" SG_ 1160 ACM_in_Plant_Mode 0;
BA_ "GenSigStartValue" SG_ 1160 ACM_in_Plant_Mode 1;
BA_ "GenSigSendType" SG_ 1160 ACM_PAB_Suppression 0;
BA_ "GenSigSendType" SG_ 1160 ACM_Airbag_Disabled 0;
BA_ "GenSigSendType" SG_ 1160 ACM_Development_Calibration 0;
BA_ "GenSigSendType" SG_ 1160 ACM_In_Disposal_Mode 0;
BA_ "GenSigStartValue" SG_ 1160 ACM_In_Disposal_Mode 1;
BA_ "GenSigSendType" SG_ 1160 ACM_Seatbelt_Reminder_Request 0;
BA_ "GenSigStartValue" SG_ 1160 ACM_Seatbelt_Reminder_Request 1;
BA_ "GenSigSendType" SG_ 1160 ACM_SBR_Chime_Req 0;
BA_ "GenSigStartValue" SG_ 1160 ACM_SBR_Chime_Req 1;
BA_ "GenSigSendType" SG_ 1160 ACM_SBR_Blinking_Req 0;
BA_ "GenSigStartValue" SG_ 1160 ACM_SBR_Blinking_Req 1;
BA_ "GenSigSendType" SG_ 262 Checksum_0x106 0;
BA_ "GenSigSendType" SG_ 262 Rolling_Counter_0x106 0;
BA_ "GenSigInvalidValue" SG_ 262 Rolling_Counter_0x106 15;
BA_ "GenSigSendType" SG_ 262 BCM_HighBeamSts 0;
BA_ "GenSigSendType" SG_ 262 BCM_LowBeamSts 0;
BA_ "GenSigSendType" SG_ 262 BCM_PosLmpSts 0;
BA_ "GenSigSendType" SG_ 262 BCM_TurnIndicatorSts 0;
BA_ "GenSigSendType" SG_ 262 BCM_DayRunningLampSts_reserved 0;
BA_ "GenSigSendType" SG_ 262 BCM_ReverseLightSts 0;
BA_ "GenSigSendType" SG_ 262 BCM_StopLightSts 0;
BA_ "GenSigSendType" SG_ 262 BCM_Fr_Dimming_dome_lampSts 0;
BA_ "GenSigSendType" SG_ 262 BCM_Heated_rearglass 0;
BA_ "GenSigSendType" SG_ 262 BCM_BsdLightSts 0;
BA_ "GenSigSendType" SG_ 262 BCM_STAT_LightActivation 0;
BA_ "GenSigStartValue" SG_ 262 BCM_STAT_LightActivation 7;
BA_ "GenSigSendType" SG_ 262 BCM_STAT_InteriorLight 0;
BA_ "GenSigStartValue" SG_ 262 BCM_STAT_InteriorLight 3;
BA_ "GenSigSendType" SG_ 265 Checksum_0x109 0;
BA_ "GenSigSendType" SG_ 265 Rolling_Counter_0x109 0;
BA_ "GenSigInvalidValue" SG_ 265 Rolling_Counter_0x109 15;
BA_ "GenSigSendType" SG_ 265 BCM_STAT_HazardWarn 0;
BA_ "GenSigSendType" SG_ 265 BCM_STAT_Horn_Reserved 0;
BA_ "GenSigSendType" SG_ 265 BCM_STAT_WiperStalkSW 0;
BA_ "GenSigInvalidValue" SG_ 265 BCM_STAT_WiperStalkSW 7;
BA_ "GenSigStartValue" SG_ 265 BCM_STAT_WiperStalkSW 7;
BA_ "GenSigSendType" SG_ 265 BCM_STAT_WiperStalkSW2 0;
BA_ "GenSigInvalidValue" SG_ 265 BCM_STAT_WiperStalkSW2 7;
BA_ "GenSigStartValue" SG_ 265 BCM_STAT_WiperStalkSW2 7;
BA_ "GenSigSendType" SG_ 265 BCM_LigntSensor 0;
BA_ "GenSigSendType" SG_ 265 BCM_STAT_lampStalkSW1 0;
BA_ "GenSigInvalidValue" SG_ 265 BCM_STAT_lampStalkSW1 7;
BA_ "GenSigStartValue" SG_ 265 BCM_STAT_lampStalkSW1 7;
BA_ "GenSigSendType" SG_ 265 BCM_STAT_lampStalkSW2 0;
BA_ "GenSigInvalidValue" SG_ 265 BCM_STAT_lampStalkSW2 3;
BA_ "GenSigStartValue" SG_ 265 BCM_STAT_lampStalkSW2 3;
BA_ "GenSigSendType" SG_ 266 Checksum_0x10a 0;
BA_ "GenSigSendType" SG_ 266 Rolling_Counter_0x10a 0;
BA_ "GenSigInvalidValue" SG_ 266 Rolling_Counter_0x10a 15;
BA_ "GenSigSendType" SG_ 266 BCM_LVTop_up 0;
BA_ "GenSigSendType" SG_ 266 Ubatt_Reserved 0;
BA_ "GenSigInvalidValue" SG_ 266 Ubatt_Reserved 16383;
BA_ "GenSigStartValue" SG_ 266 Ubatt_Reserved 9000;
BA_ "GenSigSendType" SG_ 274 Checksum_0x112 0;
BA_ "GenSigSendType" SG_ 274 Rolling_Counter_0x112 0;
BA_ "GenSigInvalidValue" SG_ 274 Rolling_Counter_0x112 15;
BA_ "GenSigSendType" SG_ 274 STAT_Terminal 0;
BA_ "GenSigSendType" SG_ 274 STAT_CL30s_L_Reserved 0;
BA_ "GenSigStartValue" SG_ 274 STAT_CL30s_L_Reserved 3;
BA_ "GenSigSendType" SG_ 834 Checksum_0x342 0;
BA_ "GenSigSendType" SG_ 834 RollingCounter_0x342 0;
BA_ "GenSigInvalidValue" SG_ 834 RollingCounter_0x342 15;
BA_ "GenSigSendType" SG_ 834 ABS_LRWhlSpdRaw 0;
BA_ "GenSigInvalidValue" SG_ 834 ABS_LRWhlSpdRaw 32767;
BA_ "GenSigSendType" SG_ 834 ABS_LRWhlSpdRawValid 0;
BA_ "GenSigSendType" SG_ 834 ABS_RRWhlSpdRaw 0;
BA_ "GenSigInvalidValue" SG_ 834 ABS_RRWhlSpdRaw 32767;
BA_ "GenSigSendType" SG_ 834 ABS_RRWhlSpdRawValid 0;
BA_ "GenSigSendType" SG_ 834 ABS_VehSpd 0;
BA_ "GenSigInvalidValue" SG_ 834 ABS_VehSpd 32767;
BA_ "GenSigSendType" SG_ 834 ABS_VehSpdValid 0;
BA_ "GenSigSendType" SG_ 322 Checksum_0x142 0;
BA_ "GenSigSendType" SG_ 322 RollingCounter_0x142 0;
BA_ "GenSigInvalidValue" SG_ 322 RollingCounter_0x142 15;
BA_ "GenSigSendType" SG_ 322 AbsDiagSessionLampReq_Reserved 0;
BA_ "GenSigSendType" SG_ 322 ABS_AbsCtrlActv 0;
BA_ "GenSigSendType" SG_ 322 ABS_EbdFlgFlt 0;
BA_ "GenSigSendType" SG_ 322 ABS_AbsFlgFlt 0;
BA_ "GenSigSendType" SG_ 322 ABS_ESS_Active 0;
BA_ "GenSigSendType" SG_ 322 ABS_LowBrakeFluid 0;
BA_ "GenSigSendType" SG_ 306 Checksum_0x132 0;
BA_ "GenSigSendType" SG_ 306 RollingCounter_0x132 0;
BA_ "GenSigInvalidValue" SG_ 306 RollingCounter_0x132 15;
BA_ "GenSigSendType" SG_ 306 ESC_HSA_Control_Status 0;
BA_ "GenSigSendType" SG_ 306 ESC_HSA_Status_Fault 0;
BA_ "GenSigSendType" SG_ 306 ESC_TcsDisableSts 0;
BA_ "GenSigInvalidValue" SG_ 306 ESC_TcsDisableSts 3;
BA_ "GenSigSendType" SG_ 306 ESC_TcsCtrlActv 0;
BA_ "GenSigSendType" SG_ 306 ESC_TcsFlgFlt 0;
BA_ "GenSigSendType" SG_ 306 ESC_EscDisableSts 0;
BA_ "GenSigSendType" SG_ 306 ESC_EscCtrlActv 0;
BA_ "GenSigSendType" SG_ 306 ESC_EscFlgFlt 0;
BA_ "GenSigSendType" SG_ 306 ESC_HBAFlgFlt 0;
BA_ "GenSigSendType" SG_ 306 ESC_HbaCtrlActv 0;
BA_ "GenSigSendType" SG_ 306 ESC_SlopeGradeAngle 0;
BA_ "GenSigInvalidValue" SG_ 306 ESC_SlopeGradeAngle 255;
BA_ "GenSigSendType" SG_ 306 ESC_MasterCylinderPressure 0;
BA_ "GenSigInvalidValue" SG_ 306 ESC_MasterCylinderPressure 4095;
BA_ "GenSigStartValue" SG_ 306 ESC_MasterCylinderPressure 1000;
BA_ "GenSigSendType" SG_ 994 Checksum_0x3E2 0;
BA_ "GenSigSendType" SG_ 994 RollingCounter_0x3E2 0;
BA_ "GenSigInvalidValue" SG_ 994 RollingCounter_0x3E2 15;
BA_ "GenSigSendType" SG_ 994 ESC_LateralACC 0;
BA_ "GenSigInvalidValue" SG_ 994 ESC_LateralACC 255;
BA_ "GenSigStartValue" SG_ 994 ESC_LateralACC 127;
BA_ "GenSigSendType" SG_ 994 ESC_LateralACC_Valid 0;
BA_ "GenSigSendType" SG_ 994 ESC_LongitudeACC 0;
BA_ "GenSigInvalidValue" SG_ 994 ESC_LongitudeACC 1023;
BA_ "GenSigStartValue" SG_ 994 ESC_LongitudeACC 511;
BA_ "GenSigSendType" SG_ 994 ESC_LongitudeACC_Valid 0;
BA_ "GenSigSendType" SG_ 994 ESC_VehDynYawRate 0;
BA_ "GenSigInvalidValue" SG_ 994 ESC_VehDynYawRate 16383;
BA_ "GenSigSendType" SG_ 994 ESC_VehDynYawRate_Valid 0;
BA_ "GenSigSendType" SG_ 382 Checksum_0x17E 0;
BA_ "GenSigSendType" SG_ 382 Rolling_counter_0x17E 0;
BA_ "GenSigInvalidValue" SG_ 382 Rolling_counter_0x17E 15;
BA_ "GenSigSendType" SG_ 382 SAS_SteerWheelAngle 0;
BA_ "GenSigInvalidValue" SG_ 382 SAS_SteerWheelAngle 65535;
BA_ "GenSigStartValue" SG_ 382 SAS_SteerWheelAngle 32773;
BA_ "GenSigSendType" SG_ 382 SAS_SteeringAngleValid 0;
BA_ "GenSigSendType" SG_ 382 SAS_SASStsSnsr 0;
BA_ "GenSigSendType" SG_ 382 SAS_SteerWhlRotSpd 0;
BA_ "GenSigInvalidValue" SG_ 382 SAS_SteerWhlRotSpd 16383;
BA_ "GenSigSendType" SG_ 382 SAS_SteerWhlRotSpdStatus 0;
BA_ "GenSigSendType" SG_ 382 SAS_Calibrated 0;
BA_ "GenSigSendType" SG_ 382 SAS_SASFailure 0;
BA_ "GenSigSendType" SG_ 617 Checksum_0x269 0;
BA_ "GenSigSendType" SG_ 617 RollingCounter_0x269 0;
BA_ "GenSigInvalidValue" SG_ 617 RollingCounter_0x269 15;
BA_ "GenSigSendType" SG_ 617 VCU_VehicleHVStatus 0;
BA_ "GenSigInvalidValue" SG_ 617 VCU_VehicleHVStatus 3;
BA_ "GenSigSendType" SG_ 617 VCU_ActualGear 0;
BA_ "GenSigInvalidValue" SG_ 617 VCU_ActualGear 7;
BA_ "GenSigStartValue" SG_ 617 VCU_ActualGear 2;
BA_ "GenSigSendType" SG_ 617 VCU_ActualGearValid 0;
BA_ "GenSigInvalidValue" SG_ 617 VCU_ActualGearValid 1;
BA_ "GenSigSendType" SG_ 617 VCU_AccPedalPosition 0;
BA_ "GenSigInvalidValue" SG_ 617 VCU_AccPedalPosition 255;
BA_ "GenSigSendType" SG_ 617 VCU_AccPedalPositionValid 0;
BA_ "GenSigInvalidValue" SG_ 617 VCU_AccPedalPositionValid 1;
BA_ "GenSigSendType" SG_ 617 VCU_TqReductionRqstResponse_Reserved 0;
BA_ "GenSigStartValue" SG_ 617 VCU_TqReductionRqstResponse_Reserved 1;
BA_ "GenSigSendType" SG_ 617 VCU_BrakePedalSts 0;
BA_ "GenSigInvalidValue" SG_ 617 VCU_BrakePedalSts 3;
BA_ "GenSigSendType" SG_ 814 CCU_ExternalTemperature 0;
BA_ "GenSigInvalidValue" SG_ 814 CCU_ExternalTemperature 255;
BA_ "GenSigStartValue" SG_ 814 CCU_ExternalTemperature 255;
BA_ "GenSigSendType" SG_ 814 CCU_ExternalTemperatureFailSts 0;
BA_ "GenSigInvalidValue" SG_ 814 CCU_ExternalTemperatureFailSts 1;
BA_ "GenSigStartValue" SG_ 814 CCU_ExternalTemperatureFailSts 1;
BA_ "GenSigSendType" SG_ 1087 IPC_Sec 0;
BA_ "GenSigInvalidValue" SG_ 1087 IPC_Sec 63;
BA_ "GenSigSendType" SG_ 1087 IPC_Min 0;
BA_ "GenSigInvalidValue" SG_ 1087 IPC_Min 63;
BA_ "GenSigSendType" SG_ 1087 IPC_Hour 0;
BA_ "GenSigInvalidValue" SG_ 1087 IPC_Hour 31;
BA_ "GenSigSendType" SG_ 1087 IPC_Day 0;
BA_ "GenSigInvalidValue" SG_ 1087 IPC_Day 31;
BA_ "GenSigStartValue" SG_ 1087 IPC_Day 1;
BA_ "GenSigSendType" SG_ 1087 IPC_Month 0;
BA_ "GenSigInvalidValue" SG_ 1087 IPC_Month 15;
BA_ "GenSigStartValue" SG_ 1087 IPC_Month 1;
BA_ "GenSigSendType" SG_ 1087 IPC_Year 0;
BA_ "GenSigInvalidValue" SG_ 1087 IPC_Year 255;
BA_ "GenSigSendType" SG_ 1087 IPC_SelfCheckStatus 0;
BA_ "GenSigSendType" SG_ 524 Checksum_0x20C 0;
BA_ "GenSigSendType" SG_ 524 Rolling_Counter_0x20C 0;
BA_ "GenSigInvalidValue" SG_ 524 Rolling_Counter_0x20C 15;
BA_ "GenSigSendType" SG_ 524 IPC_ODO 0;
BA_ "GenSigInvalidValue" SG_ 524 IPC_ODO 1048575;
BA_ "GenSigSendType" SG_ 425 VCU_RegenLevel_Feed 0;
BA_ "GenSigStartValue" SG_ 425 VCU_RegenLevel_Feed 2;
BA_ "GenSigSendType" SG_ 425 VCU_RBCSts 0;
BA_ "GenSigSendType" SG_ 425 VCU_RDCSts 0;
BA_ "GenSigSendType" SG_ 425 VCU_Veh_ERR 0;
BA_ "GenSigSendType" SG_ 425 VCU_DrvSys_ERR 0;
BA_ "GenSigSendType" SG_ 425 VCU_PackSys_ERR 0;
BA_ "GenSigSendType" SG_ 425 VCU_TBOX_Veh_STS_Reserved 0;
BA_ "GenSigSendType" SG_ 425 VCU_VehChg_STS 0;
BA_ "GenSigSendType" SG_ 425 VCU_BatterVoltage_Reserved 0;
BA_ "GenSigInvalidValue" SG_ 425 VCU_BatterVoltage_Reserved 255;
BA_ "GenSigStartValue" SG_ 425 VCU_BatterVoltage_Reserved 171;
BA_ "GenSigSendType" SG_ 425 VCU_BatteryVoltErr_Reserved 0;
BA_ "GenSigSendType" SG_ 425 VCU_MotorCoolingCircuitErr_Reserved 0;
BA_ "GenSigSendType" SG_ 425 VCU_PackCoolingCircuitErr_Reserved 0;
BA_ "GenSigSendType" SG_ 425 VCU_VehicleHVStatus 0;
BA_ "GenSigInvalidValue" SG_ 425 VCU_VehicleHVStatus 3;
BA_ "GenSigSendType" SG_ 425 VCU_InstantPowerConsump 0;
BA_ "GenSigInvalidValue" SG_ 425 VCU_InstantPowerConsump 1023;
BA_ "GenSigSendType" SG_ 425 VCU_AveragePowerConsump 0;
BA_ "GenSigInvalidValue" SG_ 425 VCU_AveragePowerConsump 1023;
BA_ "GenSigSendType" SG_ 425 VCU_BrakePedalSts 0;
BA_ "GenSigSendType" SG_ 504 Checksum_0x1F8 0;
BA_ "GenSigSendType" SG_ 504 Rolling_Counter_0x1F8 0;
BA_ "GenSigInvalidValue" SG_ 504 Rolling_Counter_0x1F8 15;
BA_ "GenSigSendType" SG_ 504 EDS_output_trq_FR 0;
BA_ "GenSigInvalidValue" SG_ 504 EDS_output_trq_FR 65535;
BA_ "GenSigStartValue" SG_ 504 EDS_output_trq_FR 4000;
BA_ "GenSigSendType" SG_ 504 EDS_output_trqValid_FR 0;
BA_ "GenSigSendType" SG_ 504 EDS_Spd_FR 0;
BA_ "GenSigInvalidValue" SG_ 504 EDS_Spd_FR 65535;
BA_ "GenSigStartValue" SG_ 504 EDS_Spd_FR 20000;
BA_ "GenSigSendType" SG_ 504 EDS_SpdValid_FR 0;
BA_ "GenSigSendType" SG_ 504 EDS_MotorDriveSts_FR 0;
BA_ "GenSigInvalidValue" SG_ 504 EDS_MotorDriveSts_FR 3;
BA_ "GenSigSendType" SG_ 504 EDS_Work_STS_FR 0;
BA_ "GenSigInvalidValue" SG_ 504 EDS_Work_STS_FR 15;
BA_ "GenSigSendType" SG_ 504 EDS_powoff_req_FR 0;
BA_ "GenSigSendType" SG_ 1281 BCM_sourceID 0;
BA_ "GenSigSendType" SG_ 1281 BCM_CBV 0;
BA_ "GenSigSendType" SG_ 1281 BCM_Data0 0;
BA_ "GenSigSendType" SG_ 1281 BCM_Data1 0;
BA_ "GenSigSendType" SG_ 1281 BCM_Data2 0;
BA_ "GenSigSendType" SG_ 1281 BCM_Data3 0;
BA_ "GenSigSendType" SG_ 1281 BCM_Data4 0;
BA_ "GenSigSendType" SG_ 1281 BCM_Data5 0;
BA_ "GenSigSendType" SG_ 1288 ACM_sourceID 0;
BA_ "GenSigSendType" SG_ 1288 ACM_CBV 0;
BA_ "GenSigSendType" SG_ 1288 ACM_Data0 0;
BA_ "GenSigSendType" SG_ 1288 ACM_Data1 0;
BA_ "GenSigSendType" SG_ 1288 ACM_Data2 0;
BA_ "GenSigSendType" SG_ 1288 ACM_Data3 0;
BA_ "GenSigSendType" SG_ 1288 ACM_Data4 0;
BA_ "GenSigSendType" SG_ 1288 ACM_Data5 0;
BA_ "GenSigSendType" SG_ 1344 BSD_sourceID 0;
BA_ "GenSigSendType" SG_ 1344 BSD_CBV 0;
BA_ "GenSigSendType" SG_ 1344 BSD_Data0 0;
BA_ "GenSigSendType" SG_ 1344 BSD_Data1 0;
BA_ "GenSigSendType" SG_ 1344 BSD_Data2 0;
BA_ "GenSigSendType" SG_ 1344 BSD_Data3 0;
BA_ "GenSigSendType" SG_ 1344 BSD_Data4 0;
BA_ "GenSigSendType" SG_ 1344 BSD_Data5 0;
BA_ "GenSigSendType" SG_ 1282 GW_sourceID 0;
BA_ "GenSigSendType" SG_ 1282 GW_CBV 0;
BA_ "GenSigSendType" SG_ 1282 GW_Data0 0;
BA_ "GenSigSendType" SG_ 1282 GW_Data1 0;
BA_ "GenSigSendType" SG_ 1282 GW_Data2 0;
BA_ "GenSigSendType" SG_ 1282 GW_Data3 0;
BA_ "GenSigSendType" SG_ 1282 GW_Data4 0;
BA_ "GenSigSendType" SG_ 1282 GW_Data5 0;
BA_ "GenSigSendType" SG_ 1672 ACM_DiagReqData0 0;
BA_ "GenSigSendType" SG_ 1672 ACM_DiagReqData1 0;
BA_ "GenSigSendType" SG_ 1672 ACM_DiagReqData2 0;
BA_ "GenSigSendType" SG_ 1672 ACM_DiagReqData3 0;
BA_ "GenSigSendType" SG_ 1672 ACM_DiagReqData4 0;
BA_ "GenSigSendType" SG_ 1672 ACM_DiagReqData5 0;
BA_ "GenSigSendType" SG_ 1672 ACM_DiagReqData6 0;
BA_ "GenSigSendType" SG_ 1672 ACM_DiagReqData7 0;
BA_ "GenSigSendType" SG_ 1544 ACM_DiagRespData0 0;
BA_ "GenSigSendType" SG_ 1544 ACM_DiagRespData1 0;
BA_ "GenSigSendType" SG_ 1544 ACM_DiagRespData2 0;
BA_ "GenSigSendType" SG_ 1544 ACM_DiagRespData3 0;
BA_ "GenSigSendType" SG_ 1544 ACM_DiagRespData4 0;
BA_ "GenSigSendType" SG_ 1544 ACM_DiagRespData5 0;
BA_ "GenSigSendType" SG_ 1544 ACM_DiagRespData6 0;
BA_ "GenSigSendType" SG_ 1544 ACM_DiagRespData7 0;
BA_ "GenSigSendType" SG_ 1791 GW_DiagFunctionalAddressingData0 0;
BA_ "GenSigSendType" SG_ 1791 GW_DiagFunctionalAddressingData1 0;
BA_ "GenSigSendType" SG_ 1791 GW_DiagFunctionalAddressingData2 0;
BA_ "GenSigSendType" SG_ 1791 GW_DiagFunctionalAddressingData3 0;
BA_ "GenSigSendType" SG_ 1791 GW_DiagFunctionalAddressingData4 0;
BA_ "GenSigSendType" SG_ 1791 GW_DiagFunctionalAddressingData5 0;
BA_ "GenSigSendType" SG_ 1791 GW_DiagFunctionalAddressingData6 0;
BA_ "GenSigSendType" SG_ 1791 GW_DiagFunctionalAddressingData7 0;
VAL_ 133 Rolling_Counter_0x85 15 "Invalid";
VAL_ 133 ACM_Crash_Sts 3 "Invalid Value" 2 "Invalid Value" 1 "Crash_Detected" 0 "No_Event";
VAL_ 133 ACM_Airbag_Deployment_Status 3 "Invalid Value" 2 "Invalid Value" 1 "Airbag_Deployment" 0 "No_Airbag_Deployment";
VAL_ 133 ACM_Crash_Intensity 7 "Invalid_Value" 6 "Invalid_Value" 5 "Invalid_Value" 4 "Invalid_Value" 3 "Crash_Intensity_3" 2 "Crash_Intensity_2" 1 "Crash_Intensity_1" 0 "No_Crash";
VAL_ 133 ACM_Front_Crash 3 "Invalid Value" 2 "Invalid Value" 1 "Front_Crash_Detected" 0 "No_Event";
VAL_ 133 ACM_DriverSide_Crash 3 "Invalid Value" 2 "Invalid Value" 1 "Driverside_Crash_Detected" 0 "No_Event";
VAL_ 133 ACM_PassSide_Crash 3 "Invalid Value" 2 "Invalid Value" 1 "PassSide_Crash_Detected" 0 "No_Event";
VAL_ 133 ACM_Rear_Crash 3 "Invalid Value" 2 "Invalid Value" 1 "Rear_Crash_Detected" 0 "No_Event";
VAL_ 133 ACM_Rollover_Crash 3 "Invalid Value" 2 "Invalid Value" 1 "Rollover_Crash_Detected" 0 "No_Event";
VAL_ 897 Rolling_Counter_0x381 15 "Invalid";
VAL_ 897 ACM_Seat_Occupancy_Passenger 3 "Failure" 2 "Not_Available" 1 "Seat Occupied" 0 "Seat_Not_Occupied";
VAL_ 897 ACM_Seat_Occupancy_2nd_Row_Dri_reserved 3 "Failure" 2 "Not_Available" 1 "Seat Occupied" 0 "Seat_Not_Occupied";
VAL_ 897 ACM_Seat_Occupancy_2nd_Row_Pas_reserved 3 "Failure" 2 "Not_Available" 1 "Seat Occupied" 0 "Seat_Not_Occupied";
VAL_ 897 ACM_Seat_Occupancy_2nd_Row_Mid_reserved 3 "Failure" 2 "Not_Available" 1 "Seat Occupied" 0 "Seat_Not_Occupied";
VAL_ 897 ACM_Seat_Belt_Status_Passenger 3 "Failure" 2 "Not_Available" 1 "Buckled" 0 "Not_buckled";
VAL_ 897 ACM_Seat_Belt_Status_Driver 3 "Failure" 2 "Not_Available" 1 "Buckled" 0 "Not_buckled";
VAL_ 897 ACM_Seat_Belt_Status_2nd_Row_Dri_reserved 3 "Failure" 2 "Not_Available" 1 "Buckled" 0 "Not_buckled";
VAL_ 897 ACM_Seat_Belt_Status_2nd_Row_Mid_reserved 3 "Failure" 2 "Not_Available" 1 "Buckled" 0 "Not_buckled";
VAL_ 897 ACM_Seat_Belt_Status_2nd_Row_Pas_reserved 3 "Failure" 2 "Not_Available" 1 "Buckled" 0 "Not_buckled";
VAL_ 897 ACM_Seat_Belt_Status_3rd_Row_Dri_reserved 3 "Failure" 2 "Not_Available" 1 "Buckled" 0 "Not_buckled";
VAL_ 897 ACM_Seat_Belt_Status_3rd_Row_Pas_reserved 3 "Failure" 2 "Not_Available" 1 "Buckled" 0 "Not_buckled";
VAL_ 1160 Rolling_Counter_0x488 15 "Invalid";
VAL_ 1160 ACM_Malfunction 0 "ACM_Failure" 1 "ACM_Normal_Operation";
VAL_ 1160 ACM_Pre_Drive_Check 0 "ACM_Pre_Drive_Check" 1 "ACM_Normal_Operation";
VAL_ 1160 ACM_in_Plant_Mode 0 "ACM_in_Plant_Mode" 1 "ACM_in_Normal_Mode";
VAL_ 1160 ACM_PAB_Suppression 0 "Not_Suppressed" 1 "Suppressed" 2 "Function Failure" 3 "Invalid_Value";
VAL_ 1160 ACM_Airbag_Disabled 0 "ACM_AirBag_Disabled" 1 "ACM_Normal_Operation";
VAL_ 1160 ACM_Development_Calibration 0 "ACM_Dev_Calibrated" 1 "ACM_Normal_Operation";
VAL_ 1160 ACM_In_Disposal_Mode 0 "ACM_In_Disposal_Mode" 1 "ACM_Normal_Operation";
VAL_ 1160 ACM_Seatbelt_Reminder_Request 0 "Seatbelt reminder NOT activated" 1 "Seatbelt reminder activated";
VAL_ 1160 ACM_SBR_Chime_Req 0 "No Active Chime" 1 "Active Chime";
VAL_ 1160 ACM_SBR_Blinking_Req 0 "No Blinking" 1 "Blinking 1Hz";
VAL_ 262 Rolling_Counter_0x106 15 "Invalid";
VAL_ 262 BCM_HighBeamSts 0 "OFF" 1 "ON" 2 "Fault (Reserved)" 3 "Signal Invalid";
VAL_ 262 BCM_LowBeamSts 0 "OFF" 1 "ON" 2 "Fault (Reserved)" 3 "Signal Invalid";
VAL_ 262 BCM_PosLmpSts 0 "OFF" 1 "ON" 2 "Fault (Reserved)" 3 "Signal Invalid";
VAL_ 262 BCM_TurnIndicatorSts 0 "OFF" 1 "Left On" 2 "Right On" 3 "Left and Right On";
VAL_ 262 BCM_DayRunningLampSts_reserved 0 "OFF" 1 "ON" 2 "Fault (Reserved)" 3 "Signal Invalid";
VAL_ 262 BCM_ReverseLightSts 0 "OFF" 1 "ON" 2 "Fault (Reserved)" 3 "Signal Invalid";
VAL_ 262 BCM_StopLightSts 0 "OFF" 1 "ON" 2 "Fault (Reserved)" 3 "Signal Invalid";
VAL_ 262 BCM_Fr_Dimming_dome_lampSts 0 "OFF" 1 "ON" 2 "Fault (Reserved)" 3 "Signal Invalid";
VAL_ 262 BCM_Heated_rearglass 0 "OFF" 1 "ON" 2 "Fault (Reserved)" 3 "Signal Invalid";
VAL_ 262 BCM_BsdLightSts 0 "OFF" 1 "Left On" 2 "Right On" 3 "Left and Right On";
VAL_ 262 BCM_STAT_LightActivation 7 "Signal invalid" 6 "Reserved" 5 "Reserved" 4 "Reserved" 3 "AutoLight" 2 "LowBeam" 1 "PositionLight" 0 "OFF";
VAL_ 262 BCM_STAT_InteriorLight 3 "Signal invalid" 2 "Reserved" 1 "ON" 0 "OFF";
VAL_ 265 Rolling_Counter_0x109 15 "Invalid";
VAL_ 265 BCM_STAT_HazardWarn 3 "Signal invalid" 2 "Reserved" 1 "Active" 0 "Not active";
VAL_ 265 BCM_STAT_Horn_Reserved 3 "Signal invalid" 2 "Reserved" 1 "ON" 0 "OFF";
VAL_ 265 BCM_STAT_WiperStalkSW 7 "Invalid" 6 "Reserved" 5 "Reserved" 4 "High" 3 "Low/Mist" 2 "Auto" 1 "OFF" 0 "Mist (reserved)";
VAL_ 265 BCM_STAT_WiperStalkSW2 7 "Invalid" 6 "Reserved" 5 "Reserved" 4 "wash(Front wash)" 3 "wiper&wash" 2 "wiper (rear wiper)" 1 "OFF(rear wiper)" 0 "wiper&wash(rear wiper and rear wash)";
VAL_ 265 BCM_LigntSensor 1 "invalid" 0 "valid";
VAL_ 265 BCM_STAT_lampStalkSW1 7 "Invalid" 6 "Reserved" 5 "Reserved" 4 "Reserved" 3 "OFF" 2 "positionlight" 1 "Lowbeam" 0 "Auto";
VAL_ 265 BCM_STAT_lampStalkSW2 3 "Invalid" 2 "neutral status" 1 "HighBeam" 0 "FlashHighBeam";
VAL_ 266 Rolling_Counter_0x10a 15 "Invalid";
VAL_ 266 BCM_LVTop_up 1 "start Top up" 0 "stop Top up";
VAL_ 274 Rolling_Counter_0x112 15 "Invalid";
VAL_ 274 STAT_Terminal 7 "Signal invalid" 6 "Reserved" 5 "Reserved" 4 "SW update OTA (Not used in VFe34)" 3 "Engine start (eMotor running)" 2 "ON (Driver Present)" 1 "ACC (Park)" 0 "OFF(Comfort Enable)";
VAL_ 274 STAT_CL30s_L_Reserved 3 "Signal invalid" 2 "Failure" 1 "ON" 0 "OFF";
VAL_ 834 RollingCounter_0x342 15 "Invalid";
VAL_ 834 ABS_LRWhlSpdRaw 32767 "Invalid";
VAL_ 834 ABS_LRWhlSpdRawValid 1 "Valid" 0 "Invalid";
VAL_ 834 ABS_RRWhlSpdRaw 32767 "Invalid";
VAL_ 834 ABS_RRWhlSpdRawValid 1 "Valid" 0 "Invalid";
VAL_ 834 ABS_VehSpd 32767 "Invalid";
VAL_ 834 ABS_VehSpdValid 1 "Valid" 0 "Invalid";
VAL_ 322 RollingCounter_0x142 15 "Invalid";
VAL_ 322 AbsDiagSessionLampReq_Reserved 1 "lamp on" 0 "lamp off";
VAL_ 322 ABS_AbsCtrlActv 1 "active" 0 "inactive";
VAL_ 322 ABS_EbdFlgFlt 1 "failure" 0 "no failure";
VAL_ 322 ABS_AbsFlgFlt 1 "failure" 0 "no failure";
VAL_ 322 ABS_ESS_Active 1 "active" 0 "inactive";
VAL_ 322 ABS_LowBrakeFluid 1 "failure" 0 "no failure";
VAL_ 306 RollingCounter_0x132 15 "Invalid";
VAL_ 306 ESC_HSA_Control_Status 1 "active" 0 "inactive";
VAL_ 306 ESC_HSA_Status_Fault 1 " HSA Defective" 0 "HSA Normale";
VAL_ 306 ESC_TcsDisableSts 3 "signal invalid" 2 "reservred" 1 "disabled" 0 "enabled";
VAL_ 306 ESC_TcsCtrlActv 1 "active" 0 "inactive";
VAL_ 306 ESC_TcsFlgFlt 1 "failure" 0 "no failure";
VAL_ 306 ESC_EscDisableSts 1 "disabled" 0 "enabled";
VAL_ 306 ESC_EscCtrlActv 1 "active" 0 "inactive";
VAL_ 306 ESC_EscFlgFlt 1 "failure" 0 "no failure";
VAL_ 306 ESC_HBAFlgFlt 1 "failure" 0 "no failure";
VAL_ 306 ESC_HbaCtrlActv 1 "active" 0 "inactive";
VAL_ 306 ESC_SlopeGradeAngle 255 "Invalid";
VAL_ 306 ESC_MasterCylinderPressure 4095 "Invalid";
VAL_ 994 RollingCounter_0x3E2 15 "Invalid";
VAL_ 994 ESC_LateralACC 255 "Invalid";
VAL_ 994 ESC_LateralACC_Valid 1 "Valid" 0 "Invalid";
VAL_ 994 ESC_LongitudeACC 1023 "Invalid";
VAL_ 994 ESC_LongitudeACC_Valid 1 "Valid" 0 "Invalid";
VAL_ 994 ESC_VehDynYawRate 16383 "Invalid";
VAL_ 994 ESC_VehDynYawRate_Valid 1 "Valid" 0 "Invalid";
VAL_ 382 Rolling_counter_0x17E 15 "Invalid";
VAL_ 382 SAS_SteerWheelAngle 65535 "Invalid";
VAL_ 382 SAS_SteeringAngleValid 1 "Valid" 0 "Invalid";
VAL_ 382 SAS_SASStsSnsr 1 "sensor value valid" 0 "sensor value Invalid";
VAL_ 382 SAS_SteerWhlRotSpd 16383 "Invalid";
VAL_ 382 SAS_SteerWhlRotSpdStatus 1 "Valid" 0 "Invalid";
VAL_ 382 SAS_Calibrated 1 "Calibrated" 0 "Not Calibrated";
VAL_ 382 SAS_SASFailure 1 "No Failure" 0 "Failure";
VAL_ 617 RollingCounter_0x269 15 "Invalid";
VAL_ 617 VCU_VehicleHVStatus 3 "Reserved" 2 "ReadyToDrive" 1 "HV On" 0 "Not ready";
VAL_ 617 VCU_ActualGear 7 "Fault" 6 "Reserved" 5 "Reserved" 4 "Reserved" 3 "D" 2 "N" 1 "R" 0 "P reserved";
VAL_ 617 VCU_ActualGearValid 1 "nvalid" 0 "Valid";
VAL_ 617 VCU_AccPedalPosition 255 "Invalid";
VAL_ 617 VCU_AccPedalPositionValid 1 "Invalid" 0 "Valid";
VAL_ 617 VCU_TqReductionRqstResponse_Reserved 1 "active" 0 "inactive";
VAL_ 617 VCU_BrakePedalSts 3 "Invalid" 2 "Reserved" 1 "pressed" 0 "Not pressed";
VAL_ 814 CCU_ExternalTemperature 255 "Invaild";
VAL_ 814 CCU_ExternalTemperatureFailSts 1 "invalid" 0 "valid";
VAL_ 1087 IPC_Sec 63 "Invalid";
VAL_ 1087 IPC_Min 63 "Invalid";
VAL_ 1087 IPC_Hour 31 "Invalid";
VAL_ 1087 IPC_Day 31 "Invalid";
VAL_ 1087 IPC_Month 15 "Invalid";
VAL_ 1087 IPC_Year 255 "Invalid";
VAL_ 1087 IPC_SelfCheckStatus 1 "self-check finish" 0 "self-checking";
VAL_ 524 Rolling_Counter_0x20C 15 "Invalid";
VAL_ 524 IPC_ODO 1048575 "Invalid";
VAL_ 425 VCU_RegenLevel_Feed 3 "invalid" 2 "High" 1 "Low" 0 "none";
VAL_ 425 VCU_RBCSts 1 "active" 0 "incative";
VAL_ 425 VCU_RDCSts 1 "active" 0 "incative";
VAL_ 425 VCU_Veh_ERR 1 "Error" 0 "Normal";
VAL_ 425 VCU_DrvSys_ERR 1 "Error" 0 "Normal";
VAL_ 425 VCU_PackSys_ERR 1 "Error" 0 "Normal";
VAL_ 425 VCU_TBOX_Veh_STS_Reserved 3 "Other" 2 "Off" 1 "Start" 0 "Invalid";
VAL_ 425 VCU_VehChg_STS 3 "Charge fault" 2 "Charging complete" 1 "Charging in progress" 0 "Charging not in progress";
VAL_ 425 VCU_BatterVoltage_Reserved 255 "Invalid";
VAL_ 425 VCU_BatteryVoltErr_Reserved 1 "warning" 0 "no warning";
VAL_ 425 VCU_MotorCoolingCircuitErr_Reserved 1 "Error" 0 "Normal";
VAL_ 425 VCU_PackCoolingCircuitErr_Reserved 1 "Error" 0 "Normal";
VAL_ 425 VCU_VehicleHVStatus 3 "Reserved" 2 "ReadyToDrive" 1 "HV On" 0 "Not ready";
VAL_ 425 VCU_InstantPowerConsump 1023 "Invalid";
VAL_ 425 VCU_AveragePowerConsump 1023 "Invalid";
VAL_ 425 VCU_BrakePedalSts 3 "Invalid" 2 "Reserved" 1 "pressed" 0 "Not pressed";
VAL_ 504 Rolling_Counter_0x1F8 15 "Invalid";
VAL_ 504 EDS_output_trq_FR 65535 "Invalid";
VAL_ 504 EDS_output_trqValid_FR 1 "valid" 0 "invalid";
VAL_ 504 EDS_Spd_FR 65535 "Invalid";
VAL_ 504 EDS_SpdValid_FR 1 "valid" 0 "invalid";
VAL_ 504 EDS_MotorDriveSts_FR 3 "Invaild" 2 "regen control" 1 "Drive control" 0 "Zero control";
VAL_ 504 EDS_Work_STS_FR 15 "invaild" 14 "power off" 13 "Failure" 12 "after run" 11 "shut down" 5 "HVReady" 4 "normal" 3 "precharge" 2 "standby" 1 "init" 0 "default";
VAL_ 504 EDS_powoff_req_FR 1 "(Request high voltage power down)" 0 "(No request)";
